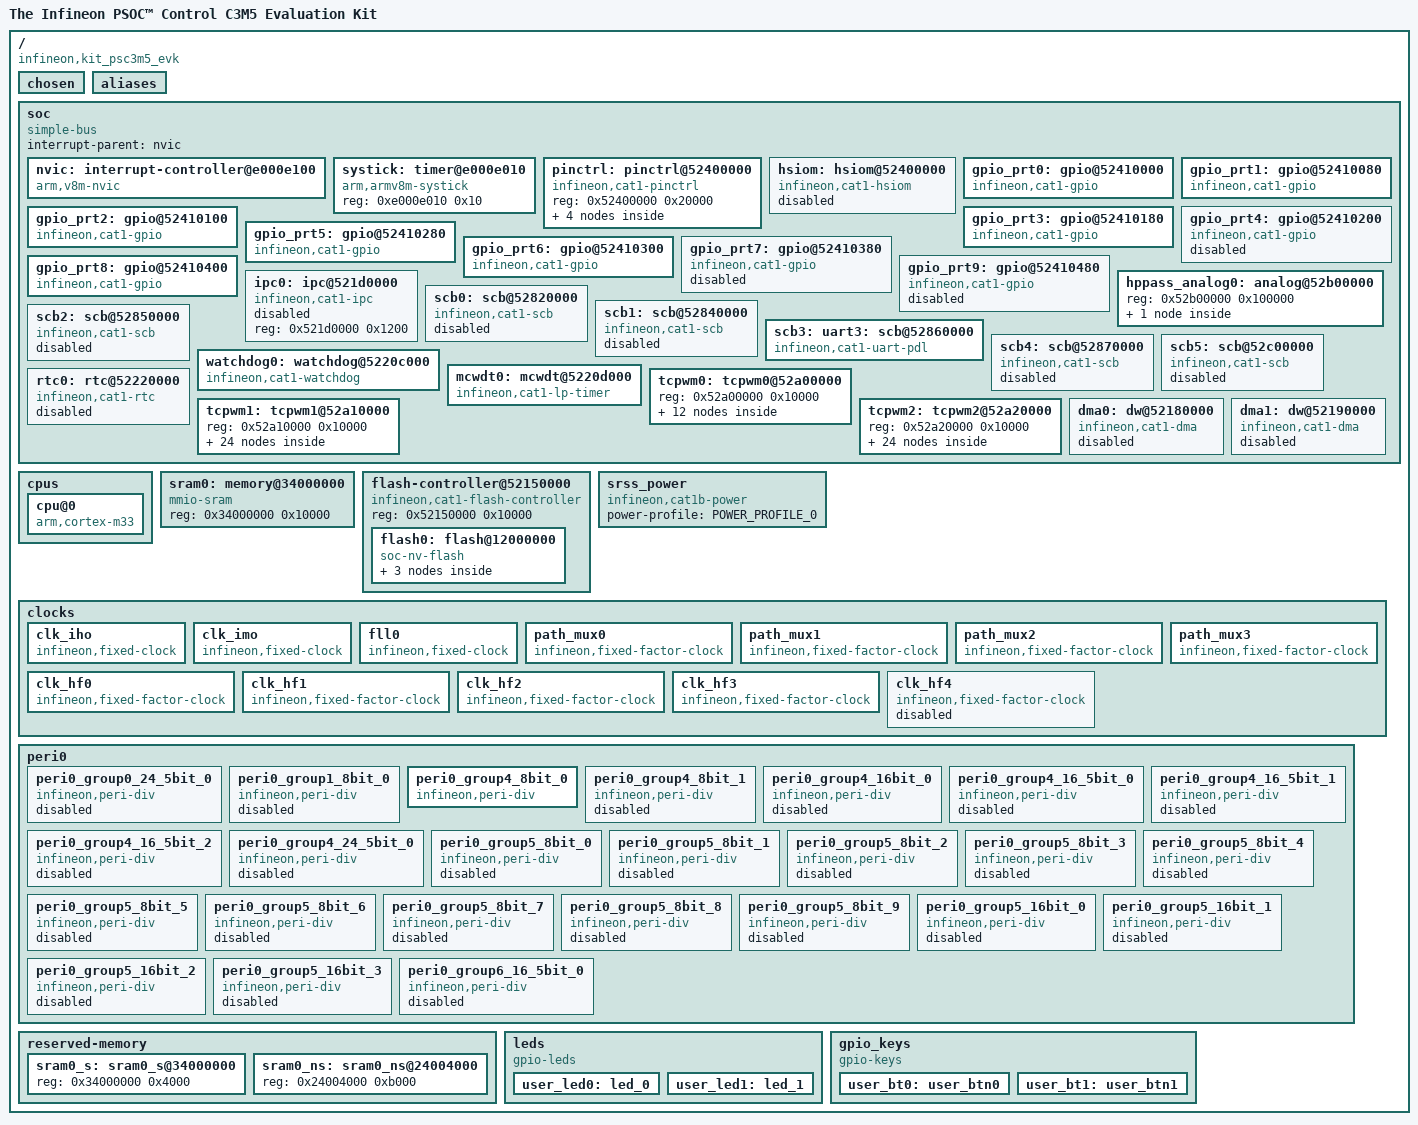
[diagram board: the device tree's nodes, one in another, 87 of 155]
/dts-v1/;

/* node '/' defined in zephyr/dts/common/skeleton.dtsi:9 */
/ {
	#address-cells = < 0x1 >;                                 /* in zephyr/dts/common/skeleton.dtsi:10 */
	#size-cells = < 0x1 >;                                    /* in zephyr/dts/common/skeleton.dtsi:11 */
	model = "The Infineon PSOC™ Control C3M5 Evaluation Kit"; /* in zephyr/boards/infineon/kit_psc3m5_evk/kit_psc3m5_evk.dts:14 */
	compatible = "infineon,kit_psc3m5_evk",
	             "infineon,PSC3M5";                           /* in zephyr/boards/infineon/kit_psc3m5_evk/kit_psc3m5_evk.dts:15 */

	/* node '/chosen' defined in zephyr/dts/common/skeleton.dtsi:13 */
	chosen {
		zephyr,sram = &sram0;            /* in zephyr/boards/infineon/kit_psc3m5_evk/kit_psc3m5_evk.dts:22 */
		zephyr,flash = &slot0_partition; /* in zephyr/boards/infineon/kit_psc3m5_evk/kit_psc3m5_evk.dts:23 */
		zephyr,console = &uart3;         /* in zephyr/boards/infineon/kit_psc3m5_evk/kit_psc3m5_evk.dts:24 */
		zephyr,shell-uart = &uart3;      /* in zephyr/boards/infineon/kit_psc3m5_evk/kit_psc3m5_evk.dts:25 */
	};

	/* node '/aliases' defined in zephyr/dts/common/skeleton.dtsi:15 */
	aliases {
		led0 = &user_led0;      /* in zephyr/boards/infineon/kit_psc3m5_evk/kit_psc3m5_evk-common.dtsi:10 */
		led1 = &user_led1;      /* in zephyr/boards/infineon/kit_psc3m5_evk/kit_psc3m5_evk-common.dtsi:11 */
		sw0 = &user_bt0;        /* in zephyr/boards/infineon/kit_psc3m5_evk/kit_psc3m5_evk-common.dtsi:12 */
		sw1 = &user_bt1;        /* in zephyr/boards/infineon/kit_psc3m5_evk/kit_psc3m5_evk-common.dtsi:13 */
		watchdog0 = &watchdog0; /* in zephyr/boards/infineon/kit_psc3m5_evk/kit_psc3m5_evk.dts:18 */
	};

	/* node '/soc' defined in zephyr/dts/arm/armv8-m.dtsi:6 */
	soc {
		#address-cells = < 0x1 >;     /* in zephyr/dts/arm/armv8-m.dtsi:7 */
		#size-cells = < 0x1 >;        /* in zephyr/dts/arm/armv8-m.dtsi:8 */
		compatible = "simple-bus";    /* in zephyr/dts/arm/armv8-m.dtsi:9 */
		interrupt-parent = < &nvic >; /* in zephyr/dts/arm/armv8-m.dtsi:10 */
		ranges;                       /* in zephyr/dts/arm/armv8-m.dtsi:11 */

		/* node '/soc/interrupt-controller@e000e100' defined in zephyr/dts/arm/armv8-m.dtsi:13 */
		nvic: interrupt-controller@e000e100 {
			#address-cells = < 0x1 >;            /* in zephyr/dts/arm/armv8-m.dtsi:14 */
			compatible = "arm,v8m-nvic";         /* in zephyr/dts/arm/armv8-m.dtsi:15 */
			reg = < 0xe000e100 0xc00 >;          /* in zephyr/dts/arm/armv8-m.dtsi:16 */
			interrupt-controller;                /* in zephyr/dts/arm/armv8-m.dtsi:17 */
			#interrupt-cells = < 0x2 >;          /* in zephyr/dts/arm/armv8-m.dtsi:18 */
			arm,num-irq-priority-bits = < 0x3 >; /* in zephyr/dts/arm/infineon/cat1b/psc3/psc3.cm33.dtsi:26 */
			phandle = < 0x1 >;                   /* in zephyr/dts/arm/armv8-m.dtsi:10 */
		};

		/* node '/soc/timer@e000e010' defined in zephyr/dts/arm/armv8-m.dtsi:21 */
		systick: timer@e000e010 {
			compatible = "arm,armv8m-systick"; /* in zephyr/dts/arm/armv8-m.dtsi:22 */
			reg = < 0xe000e010 0x10 >;         /* in zephyr/dts/arm/armv8-m.dtsi:23 */
		};

		/* node '/soc/pinctrl@52400000' defined in zephyr/dts/arm/infineon/cat1b/psc3/psc3_s.dtsi:19 */
		pinctrl: pinctrl@52400000 {
			compatible = "infineon,cat1-pinctrl"; /* in zephyr/dts/arm/infineon/cat1b/psc3/psc3_s.dtsi:20 */
			reg = < 0x52400000 0x20000 >;         /* in zephyr/dts/arm/infineon/cat1b/psc3/psc3_s.dtsi:21 */

			/* node '/soc/pinctrl@52400000/p6_0_scb3_uart_cts' defined in zephyr/dts/arm/infineon/cat1b/psc3/psc3.e-lqfp-80_s.dtsi:459 */
			p6_0_scb3_uart_cts: p6_0_scb3_uart_cts {
				pinmux = < 0x100006 >; /* in zephyr/dts/arm/infineon/cat1b/psc3/psc3.e-lqfp-80_s.dtsi:460 */
				input-enable;          /* in zephyr/boards/infineon/kit_psc3m5_evk/kit_psc3m5_evk-pinctrl.dtsi:20 */
				phandle = < 0x6 >;     /* in zephyr/boards/infineon/kit_psc3m5_evk/kit_psc3m5_evk.dts:36 */
			};

			/* node '/soc/pinctrl@52400000/p6_1_scb3_uart_rts' defined in zephyr/dts/arm/infineon/cat1b/psc3/psc3.e-lqfp-80_s.dtsi:496 */
			p6_1_scb3_uart_rts: p6_1_scb3_uart_rts {
				pinmux = < 0x100106 >; /* in zephyr/dts/arm/infineon/cat1b/psc3/psc3.e-lqfp-80_s.dtsi:497 */
				drive-push-pull;       /* in zephyr/boards/infineon/kit_psc3m5_evk/kit_psc3m5_evk-pinctrl.dtsi:16 */
				phandle = < 0x5 >;     /* in zephyr/boards/infineon/kit_psc3m5_evk/kit_psc3m5_evk.dts:36 */
			};

			/* node '/soc/pinctrl@52400000/p6_2_scb3_uart_rx' defined in zephyr/dts/arm/infineon/cat1b/psc3/psc3.e-lqfp-80_s.dtsi:533 */
			p6_2_scb3_uart_rx: p6_2_scb3_uart_rx {
				pinmux = < 0x100206 >; /* in zephyr/dts/arm/infineon/cat1b/psc3/psc3.e-lqfp-80_s.dtsi:534 */
				input-enable;          /* in zephyr/boards/infineon/kit_psc3m5_evk/kit_psc3m5_evk-pinctrl.dtsi:12 */
				phandle = < 0x4 >;     /* in zephyr/boards/infineon/kit_psc3m5_evk/kit_psc3m5_evk.dts:36 */
			};

			/* node '/soc/pinctrl@52400000/p6_3_scb3_uart_tx' defined in zephyr/dts/arm/infineon/cat1b/psc3/psc3.e-lqfp-80_s.dtsi:570 */
			p6_3_scb3_uart_tx: p6_3_scb3_uart_tx {
				pinmux = < 0x100306 >; /* in zephyr/dts/arm/infineon/cat1b/psc3/psc3.e-lqfp-80_s.dtsi:571 */
				drive-push-pull;       /* in zephyr/boards/infineon/kit_psc3m5_evk/kit_psc3m5_evk-pinctrl.dtsi:8 */
				phandle = < 0x3 >;     /* in zephyr/boards/infineon/kit_psc3m5_evk/kit_psc3m5_evk.dts:36 */
			};
		};

		/* node '/soc/hsiom@52400000' defined in zephyr/dts/arm/infineon/cat1b/psc3/psc3_s.dtsi:24 */
		hsiom: hsiom@52400000 {
			compatible = "infineon,cat1-hsiom"; /* in zephyr/dts/arm/infineon/cat1b/psc3/psc3_s.dtsi:25 */
			reg = < 0x52400000 0x4000 >;        /* in zephyr/dts/arm/infineon/cat1b/psc3/psc3_s.dtsi:26 */
			interrupts = < 0x16 0x4 >,
			             < 0x14 0x4 >;          /* in zephyr/dts/arm/infineon/cat1b/psc3/psc3_s.dtsi:27 */
			status = "disabled";                /* in zephyr/dts/arm/infineon/cat1b/psc3/psc3_s.dtsi:28 */
		};

		/* node '/soc/gpio@52410000' defined in zephyr/dts/arm/infineon/cat1b/psc3/psc3_s.dtsi:31 */
		gpio_prt0: gpio@52410000 {
			compatible = "infineon,cat1-gpio"; /* in zephyr/dts/arm/infineon/cat1b/psc3/psc3_s.dtsi:32 */
			reg = < 0x52410000 0x80 >;         /* in zephyr/dts/arm/infineon/cat1b/psc3/psc3_s.dtsi:33 */
			interrupts = < 0xa 0x4 >;          /* in zephyr/dts/arm/infineon/cat1b/psc3/psc3_s.dtsi:34 */
			gpio-controller;                   /* in zephyr/dts/arm/infineon/cat1b/psc3/psc3_s.dtsi:35 */
			ngpios = < 0x2 >;                  /* in zephyr/dts/arm/infineon/cat1b/psc3/psc3_s.dtsi:36 */
			#gpio-cells = < 0x2 >;             /* in zephyr/dts/arm/infineon/cat1b/psc3/psc3_s.dtsi:38 */
			status = "okay";                   /* in zephyr/boards/infineon/kit_psc3m5_evk/kit_psc3m5_evk-common.dtsi:48 */
		};

		/* node '/soc/gpio@52410080' defined in zephyr/dts/arm/infineon/cat1b/psc3/psc3_s.dtsi:41 */
		gpio_prt1: gpio@52410080 {
			compatible = "infineon,cat1-gpio"; /* in zephyr/dts/arm/infineon/cat1b/psc3/psc3_s.dtsi:42 */
			reg = < 0x52410080 0x80 >;         /* in zephyr/dts/arm/infineon/cat1b/psc3/psc3_s.dtsi:43 */
			interrupts = < 0xb 0x4 >;          /* in zephyr/dts/arm/infineon/cat1b/psc3/psc3_s.dtsi:44 */
			gpio-controller;                   /* in zephyr/dts/arm/infineon/cat1b/psc3/psc3_s.dtsi:45 */
			ngpios = < 0x4 >;                  /* in zephyr/dts/arm/infineon/cat1b/psc3/psc3_s.dtsi:46 */
			#gpio-cells = < 0x2 >;             /* in zephyr/dts/arm/infineon/cat1b/psc3/psc3_s.dtsi:48 */
			status = "okay";                   /* in zephyr/boards/infineon/kit_psc3m5_evk/kit_psc3m5_evk-common.dtsi:52 */
		};

		/* node '/soc/gpio@52410100' defined in zephyr/dts/arm/infineon/cat1b/psc3/psc3_s.dtsi:51 */
		gpio_prt2: gpio@52410100 {
			compatible = "infineon,cat1-gpio"; /* in zephyr/dts/arm/infineon/cat1b/psc3/psc3_s.dtsi:52 */
			reg = < 0x52410100 0x80 >;         /* in zephyr/dts/arm/infineon/cat1b/psc3/psc3_s.dtsi:53 */
			interrupts = < 0xc 0x4 >;          /* in zephyr/dts/arm/infineon/cat1b/psc3/psc3_s.dtsi:54 */
			gpio-controller;                   /* in zephyr/dts/arm/infineon/cat1b/psc3/psc3_s.dtsi:55 */
			ngpios = < 0x4 >;                  /* in zephyr/dts/arm/infineon/cat1b/psc3/psc3_s.dtsi:56 */
			#gpio-cells = < 0x2 >;             /* in zephyr/dts/arm/infineon/cat1b/psc3/psc3_s.dtsi:58 */
			status = "okay";                   /* in zephyr/boards/infineon/kit_psc3m5_evk/kit_psc3m5_evk-common.dtsi:56 */
			phandle = < 0xd >;                 /* in zephyr/boards/infineon/kit_psc3m5_evk/kit_psc3m5_evk-common.dtsi:41 */
		};

		/* node '/soc/gpio@52410180' defined in zephyr/dts/arm/infineon/cat1b/psc3/psc3_s.dtsi:61 */
		gpio_prt3: gpio@52410180 {
			compatible = "infineon,cat1-gpio"; /* in zephyr/dts/arm/infineon/cat1b/psc3/psc3_s.dtsi:62 */
			reg = < 0x52410180 0x80 >;         /* in zephyr/dts/arm/infineon/cat1b/psc3/psc3_s.dtsi:63 */
			interrupts = < 0xd 0x4 >;          /* in zephyr/dts/arm/infineon/cat1b/psc3/psc3_s.dtsi:64 */
			gpio-controller;                   /* in zephyr/dts/arm/infineon/cat1b/psc3/psc3_s.dtsi:65 */
			ngpios = < 0x4 >;                  /* in zephyr/dts/arm/infineon/cat1b/psc3/psc3_s.dtsi:66 */
			#gpio-cells = < 0x2 >;             /* in zephyr/dts/arm/infineon/cat1b/psc3/psc3_s.dtsi:68 */
			status = "okay";                   /* in zephyr/boards/infineon/kit_psc3m5_evk/kit_psc3m5_evk-common.dtsi:60 */
		};

		/* node '/soc/gpio@52410200' defined in zephyr/dts/arm/infineon/cat1b/psc3/psc3_s.dtsi:71 */
		gpio_prt4: gpio@52410200 {
			compatible = "infineon,cat1-gpio"; /* in zephyr/dts/arm/infineon/cat1b/psc3/psc3_s.dtsi:72 */
			reg = < 0x52410200 0x80 >;         /* in zephyr/dts/arm/infineon/cat1b/psc3/psc3_s.dtsi:73 */
			interrupts = < 0xe 0x4 >;          /* in zephyr/dts/arm/infineon/cat1b/psc3/psc3_s.dtsi:74 */
			gpio-controller;                   /* in zephyr/dts/arm/infineon/cat1b/psc3/psc3_s.dtsi:75 */
			ngpios = < 0x8 >;                  /* in zephyr/dts/arm/infineon/cat1b/psc3/psc3_s.dtsi:76 */
			status = "disabled";               /* in zephyr/dts/arm/infineon/cat1b/psc3/psc3_s.dtsi:77 */
			#gpio-cells = < 0x2 >;             /* in zephyr/dts/arm/infineon/cat1b/psc3/psc3_s.dtsi:78 */
		};

		/* node '/soc/gpio@52410280' defined in zephyr/dts/arm/infineon/cat1b/psc3/psc3_s.dtsi:81 */
		gpio_prt5: gpio@52410280 {
			compatible = "infineon,cat1-gpio"; /* in zephyr/dts/arm/infineon/cat1b/psc3/psc3_s.dtsi:82 */
			reg = < 0x52410280 0x80 >;         /* in zephyr/dts/arm/infineon/cat1b/psc3/psc3_s.dtsi:83 */
			interrupts = < 0xf 0x4 >;          /* in zephyr/dts/arm/infineon/cat1b/psc3/psc3_s.dtsi:84 */
			gpio-controller;                   /* in zephyr/dts/arm/infineon/cat1b/psc3/psc3_s.dtsi:85 */
			ngpios = < 0x4 >;                  /* in zephyr/dts/arm/infineon/cat1b/psc3/psc3_s.dtsi:86 */
			#gpio-cells = < 0x2 >;             /* in zephyr/dts/arm/infineon/cat1b/psc3/psc3_s.dtsi:88 */
			status = "okay";                   /* in zephyr/boards/infineon/kit_psc3m5_evk/kit_psc3m5_evk-common.dtsi:64 */
			phandle = < 0xc >;                 /* in zephyr/boards/infineon/kit_psc3m5_evk/kit_psc3m5_evk-common.dtsi:35 */
		};

		/* node '/soc/gpio@52410300' defined in zephyr/dts/arm/infineon/cat1b/psc3/psc3_s.dtsi:91 */
		gpio_prt6: gpio@52410300 {
			compatible = "infineon,cat1-gpio"; /* in zephyr/dts/arm/infineon/cat1b/psc3/psc3_s.dtsi:92 */
			reg = < 0x52410300 0x80 >;         /* in zephyr/dts/arm/infineon/cat1b/psc3/psc3_s.dtsi:93 */
			interrupts = < 0x10 0x4 >;         /* in zephyr/dts/arm/infineon/cat1b/psc3/psc3_s.dtsi:94 */
			gpio-controller;                   /* in zephyr/dts/arm/infineon/cat1b/psc3/psc3_s.dtsi:95 */
			ngpios = < 0x4 >;                  /* in zephyr/dts/arm/infineon/cat1b/psc3/psc3_s.dtsi:96 */
			#gpio-cells = < 0x2 >;             /* in zephyr/dts/arm/infineon/cat1b/psc3/psc3_s.dtsi:98 */
			status = "okay";                   /* in zephyr/boards/infineon/kit_psc3m5_evk/kit_psc3m5_evk-common.dtsi:68 */
		};

		/* node '/soc/gpio@52410380' defined in zephyr/dts/arm/infineon/cat1b/psc3/psc3_s.dtsi:101 */
		gpio_prt7: gpio@52410380 {
			compatible = "infineon,cat1-gpio"; /* in zephyr/dts/arm/infineon/cat1b/psc3/psc3_s.dtsi:102 */
			reg = < 0x52410380 0x80 >;         /* in zephyr/dts/arm/infineon/cat1b/psc3/psc3_s.dtsi:103 */
			interrupts = < 0x11 0x4 >;         /* in zephyr/dts/arm/infineon/cat1b/psc3/psc3_s.dtsi:104 */
			gpio-controller;                   /* in zephyr/dts/arm/infineon/cat1b/psc3/psc3_s.dtsi:105 */
			ngpios = < 0x8 >;                  /* in zephyr/dts/arm/infineon/cat1b/psc3/psc3_s.dtsi:106 */
			status = "disabled";               /* in zephyr/dts/arm/infineon/cat1b/psc3/psc3_s.dtsi:107 */
			#gpio-cells = < 0x2 >;             /* in zephyr/dts/arm/infineon/cat1b/psc3/psc3_s.dtsi:108 */
		};

		/* node '/soc/gpio@52410400' defined in zephyr/dts/arm/infineon/cat1b/psc3/psc3_s.dtsi:111 */
		gpio_prt8: gpio@52410400 {
			compatible = "infineon,cat1-gpio"; /* in zephyr/dts/arm/infineon/cat1b/psc3/psc3_s.dtsi:112 */
			reg = < 0x52410400 0x80 >;         /* in zephyr/dts/arm/infineon/cat1b/psc3/psc3_s.dtsi:113 */
			interrupts = < 0x12 0x4 >;         /* in zephyr/dts/arm/infineon/cat1b/psc3/psc3_s.dtsi:114 */
			gpio-controller;                   /* in zephyr/dts/arm/infineon/cat1b/psc3/psc3_s.dtsi:115 */
			ngpios = < 0x6 >;                  /* in zephyr/dts/arm/infineon/cat1b/psc3/psc3_s.dtsi:116 */
			#gpio-cells = < 0x2 >;             /* in zephyr/dts/arm/infineon/cat1b/psc3/psc3_s.dtsi:118 */
			status = "okay";                   /* in zephyr/boards/infineon/kit_psc3m5_evk/kit_psc3m5_evk-common.dtsi:72 */
			phandle = < 0xb >;                 /* in zephyr/boards/infineon/kit_psc3m5_evk/kit_psc3m5_evk-common.dtsi:21 */
		};

		/* node '/soc/gpio@52410480' defined in zephyr/dts/arm/infineon/cat1b/psc3/psc3_s.dtsi:121 */
		gpio_prt9: gpio@52410480 {
			compatible = "infineon,cat1-gpio"; /* in zephyr/dts/arm/infineon/cat1b/psc3/psc3_s.dtsi:122 */
			reg = < 0x52410480 0x80 >;         /* in zephyr/dts/arm/infineon/cat1b/psc3/psc3_s.dtsi:123 */
			interrupts = < 0x13 0x4 >;         /* in zephyr/dts/arm/infineon/cat1b/psc3/psc3_s.dtsi:124 */
			gpio-controller;                   /* in zephyr/dts/arm/infineon/cat1b/psc3/psc3_s.dtsi:125 */
			ngpios = < 0x6 >;                  /* in zephyr/dts/arm/infineon/cat1b/psc3/psc3_s.dtsi:126 */
			status = "disabled";               /* in zephyr/dts/arm/infineon/cat1b/psc3/psc3_s.dtsi:127 */
			#gpio-cells = < 0x2 >;             /* in zephyr/dts/arm/infineon/cat1b/psc3/psc3_s.dtsi:128 */
		};

		/* node '/soc/analog@52b00000' defined in zephyr/dts/arm/infineon/cat1b/psc3/psc3_s.dtsi:131 */
		hppass_analog0: analog@52b00000 {
			reg = < 0x52b00000 0x100000 >; /* in zephyr/dts/arm/infineon/cat1b/psc3/psc3_s.dtsi:132 */
			#address-cells = < 0x1 >;      /* in zephyr/dts/arm/infineon/cat1b/psc3/psc3_s.dtsi:133 */
			#size-cells = < 0x1 >;         /* in zephyr/dts/arm/infineon/cat1b/psc3/psc3_s.dtsi:134 */
			ranges;                        /* in zephyr/dts/arm/infineon/cat1b/psc3/psc3_s.dtsi:135 */

			/* node '/soc/analog@52b00000/adc@70000' defined in zephyr/dts/arm/infineon/cat1b/psc3/psc3_s.dtsi:137 */
			adc0: adc@70000 {
				compatible = "infineon,hppass-sar-adc"; /* in zephyr/dts/arm/infineon/cat1b/psc3/psc3_s.dtsi:138 */
				reg = < 0x70000 0x10000 >;              /* in zephyr/dts/arm/infineon/cat1b/psc3/psc3_s.dtsi:140 */
				interrupts = < 0x6d 0x4 >;              /* in zephyr/dts/arm/infineon/cat1b/psc3/psc3_s.dtsi:141 */
				status = "disabled";                    /* in zephyr/dts/arm/infineon/cat1b/psc3/psc3_s.dtsi:142 */
				#io-channel-cells = < 0x1 >;            /* in zephyr/dts/arm/infineon/cat1b/psc3/psc3_s.dtsi:143 */
			};
		};

		/* node '/soc/ipc@521d0000' defined in zephyr/dts/arm/infineon/cat1b/psc3/psc3_s.dtsi:147 */
		ipc0: ipc@521d0000 {
			compatible = "infineon,cat1-ipc"; /* in zephyr/dts/arm/infineon/cat1b/psc3/psc3_s.dtsi:148 */
			reg = < 0x521d0000 0x1200 >;      /* in zephyr/dts/arm/infineon/cat1b/psc3/psc3_s.dtsi:149 */
			status = "disabled";              /* in zephyr/dts/arm/infineon/cat1b/psc3/psc3_s.dtsi:150 */
			#ipc-config-cells = < 0x3 >;      /* in zephyr/dts/arm/infineon/cat1b/psc3/psc3_s.dtsi:151 */
		};

		/* node '/soc/scb@52820000' defined in zephyr/dts/arm/infineon/cat1b/psc3/psc3_s.dtsi:154 */
		scb0: scb@52820000 {
			compatible = "infineon,cat1-scb"; /* in zephyr/dts/arm/infineon/cat1b/psc3/psc3_s.dtsi:155 */
			reg = < 0x52820000 0xfd0 >;       /* in zephyr/dts/arm/infineon/cat1b/psc3/psc3_s.dtsi:156 */
			interrupts = < 0x17 0x4 >;        /* in zephyr/dts/arm/infineon/cat1b/psc3/psc3_s.dtsi:157 */
			status = "disabled";              /* in zephyr/dts/arm/infineon/cat1b/psc3/psc3_s.dtsi:158 */
		};

		/* node '/soc/scb@52840000' defined in zephyr/dts/arm/infineon/cat1b/psc3/psc3_s.dtsi:161 */
		scb1: scb@52840000 {
			compatible = "infineon,cat1-scb"; /* in zephyr/dts/arm/infineon/cat1b/psc3/psc3_s.dtsi:162 */
			reg = < 0x52840000 0xfd0 >;       /* in zephyr/dts/arm/infineon/cat1b/psc3/psc3_s.dtsi:163 */
			interrupts = < 0x1f 0x4 >;        /* in zephyr/dts/arm/infineon/cat1b/psc3/psc3_s.dtsi:164 */
			status = "disabled";              /* in zephyr/dts/arm/infineon/cat1b/psc3/psc3_s.dtsi:165 */
		};

		/* node '/soc/scb@52850000' defined in zephyr/dts/arm/infineon/cat1b/psc3/psc3_s.dtsi:168 */
		scb2: scb@52850000 {
			compatible = "infineon,cat1-scb"; /* in zephyr/dts/arm/infineon/cat1b/psc3/psc3_s.dtsi:169 */
			reg = < 0x52850000 0xfd0 >;       /* in zephyr/dts/arm/infineon/cat1b/psc3/psc3_s.dtsi:170 */
			interrupts = < 0x20 0x4 >;        /* in zephyr/dts/arm/infineon/cat1b/psc3/psc3_s.dtsi:171 */
			status = "disabled";              /* in zephyr/dts/arm/infineon/cat1b/psc3/psc3_s.dtsi:172 */
		};

		/* node '/soc/scb@52860000' defined in zephyr/dts/arm/infineon/cat1b/psc3/psc3_s.dtsi:175 */
		scb3: uart3: scb@52860000 {
			reg = < 0x52860000 0xfd0 >;                                                                    /* in zephyr/dts/arm/infineon/cat1b/psc3/psc3_s.dtsi:177 */
			interrupts = < 0x21 0x4 >;                                                                     /* in zephyr/dts/arm/infineon/cat1b/psc3/psc3_s.dtsi:178 */
			compatible = "infineon,cat1-uart-pdl";                                                         /* in zephyr/boards/infineon/kit_psc3m5_evk/kit_psc3m5_evk.dts:30 */
			status = "okay";                                                                               /* in zephyr/boards/infineon/kit_psc3m5_evk/kit_psc3m5_evk.dts:31 */
			current-speed = < 0x1c200 >;                                                                   /* in zephyr/boards/infineon/kit_psc3m5_evk/kit_psc3m5_evk.dts:32 */
			clocks = < &peri0_group4_8bit_0 >;                                                             /* in zephyr/boards/infineon/kit_psc3m5_evk/kit_psc3m5_evk.dts:34 */
			pinctrl-0 = < &p6_3_scb3_uart_tx &p6_2_scb3_uart_rx &p6_1_scb3_uart_rts &p6_0_scb3_uart_cts >; /* in zephyr/boards/infineon/kit_psc3m5_evk/kit_psc3m5_evk.dts:36 */
			pinctrl-names = "default";                                                                     /* in zephyr/boards/infineon/kit_psc3m5_evk/kit_psc3m5_evk.dts:37 */
		};

		/* node '/soc/scb@52870000' defined in zephyr/dts/arm/infineon/cat1b/psc3/psc3_s.dtsi:182 */
		scb4: scb@52870000 {
			compatible = "infineon,cat1-scb"; /* in zephyr/dts/arm/infineon/cat1b/psc3/psc3_s.dtsi:183 */
			reg = < 0x52870000 0xfd0 >;       /* in zephyr/dts/arm/infineon/cat1b/psc3/psc3_s.dtsi:184 */
			interrupts = < 0x22 0x4 >;        /* in zephyr/dts/arm/infineon/cat1b/psc3/psc3_s.dtsi:185 */
			status = "disabled";              /* in zephyr/dts/arm/infineon/cat1b/psc3/psc3_s.dtsi:186 */
		};

		/* node '/soc/scb@52c00000' defined in zephyr/dts/arm/infineon/cat1b/psc3/psc3_s.dtsi:189 */
		scb5: scb@52c00000 {
			compatible = "infineon,cat1-scb"; /* in zephyr/dts/arm/infineon/cat1b/psc3/psc3_s.dtsi:190 */
			reg = < 0x52c00000 0xfd0 >;       /* in zephyr/dts/arm/infineon/cat1b/psc3/psc3_s.dtsi:191 */
			interrupts = < 0x23 0x4 >;        /* in zephyr/dts/arm/infineon/cat1b/psc3/psc3_s.dtsi:192 */
			status = "disabled";              /* in zephyr/dts/arm/infineon/cat1b/psc3/psc3_s.dtsi:193 */
		};

		/* node '/soc/watchdog@5220c000' defined in zephyr/dts/arm/infineon/cat1b/psc3/psc3_s.dtsi:196 */
		watchdog0: watchdog@5220c000 {
			compatible = "infineon,cat1-watchdog"; /* in zephyr/dts/arm/infineon/cat1b/psc3/psc3_s.dtsi:197 */
			reg = < 0x5220c000 0x10 >;             /* in zephyr/dts/arm/infineon/cat1b/psc3/psc3_s.dtsi:198 */
			interrupts = < 0x1c 0x4 >;             /* in zephyr/dts/arm/infineon/cat1b/psc3/psc3_s.dtsi:199 */
			status = "okay";                       /* in zephyr/boards/infineon/kit_psc3m5_evk/kit_psc3m5_evk.dts:80 */
		};

		/* node '/soc/mcwdt@5220d000' defined in zephyr/dts/arm/infineon/cat1b/psc3/psc3_s.dtsi:203 */
		mcwdt0: mcwdt@5220d000 {
			compatible = "infineon,cat1-lp-timer"; /* in zephyr/dts/arm/infineon/cat1b/psc3/psc3_s.dtsi:204 */
			reg = < 0x5220d000 0x40 >;             /* in zephyr/dts/arm/infineon/cat1b/psc3/psc3_s.dtsi:205 */
			interrupts = < 0x18 0x4 >;             /* in zephyr/dts/arm/infineon/cat1b/psc3/psc3_s.dtsi:206 */
			status = "okay";                       /* in zephyr/boards/infineon/kit_psc3m5_evk/kit_psc3m5_evk.dts:84 */
		};

		/* node '/soc/rtc@52220000' defined in zephyr/dts/arm/infineon/cat1b/psc3/psc3_s.dtsi:210 */
		rtc0: rtc@52220000 {
			compatible = "infineon,cat1-rtc"; /* in zephyr/dts/arm/infineon/cat1b/psc3/psc3_s.dtsi:211 */
			reg = < 0x52220000 0xff0c >;      /* in zephyr/dts/arm/infineon/cat1b/psc3/psc3_s.dtsi:212 */
			interrupts = < 0x19 0x4 >;        /* in zephyr/dts/arm/infineon/cat1b/psc3/psc3_s.dtsi:213 */
			alarms-count = < 0x2 >;           /* in zephyr/dts/arm/infineon/cat1b/psc3/psc3_s.dtsi:214 */
			status = "disabled";              /* in zephyr/dts/arm/infineon/cat1b/psc3/psc3_s.dtsi:215 */
		};

		/* node '/soc/tcpwm0@52a00000' defined in zephyr/dts/arm/infineon/cat1b/psc3/psc3_s.dtsi:218 */
		tcpwm0: tcpwm0@52a00000 {
			reg = < 0x52a00000 0x10000 >; /* in zephyr/dts/arm/infineon/cat1b/psc3/psc3_s.dtsi:219 */
			#address-cells = < 0x1 >;     /* in zephyr/dts/arm/infineon/cat1b/psc3/psc3_s.dtsi:220 */
			#size-cells = < 0x1 >;        /* in zephyr/dts/arm/infineon/cat1b/psc3/psc3_s.dtsi:221 */

			/* node '/soc/tcpwm0@52a00000/tcpwm0_0@52a00000' defined in zephyr/dts/arm/infineon/cat1b/psc3/psc3_s.dtsi:223 */
			tcpwm0_0: tcpwm0_0@52a00000 {
				compatible = "infineon,tcpwm"; /* in zephyr/dts/arm/infineon/cat1b/psc3/psc3_s.dtsi:224 */
				reg = < 0x52a00000 0x100 >;    /* in zephyr/dts/arm/infineon/cat1b/psc3/psc3_s.dtsi:225 */
				interrupts = < 0x4c 0x4 >;     /* in zephyr/dts/arm/infineon/cat1b/psc3/psc3_s.dtsi:226 */
				resolution = < 0x20 >;         /* in zephyr/dts/arm/infineon/cat1b/psc3/psc3_s.dtsi:227 */
				status = "disabled";           /* in zephyr/dts/arm/infineon/cat1b/psc3/psc3_s.dtsi:228 */

				/* node '/soc/tcpwm0@52a00000/tcpwm0_0@52a00000/pwm0_0' defined in zephyr/dts/arm/infineon/cat1b/psc3/psc3_s.dtsi:230 */
				pwm0_0: pwm0_0 {
					compatible = "infineon,tcpwm-pwm"; /* in zephyr/dts/arm/infineon/cat1b/psc3/psc3_s.dtsi:231 */
					#pwm-cells = < 0x3 >;              /* in zephyr/dts/arm/infineon/cat1b/psc3/psc3_s.dtsi:232 */
					status = "disabled";               /* in zephyr/dts/arm/infineon/cat1b/psc3/psc3_s.dtsi:233 */
				};

				/* node '/soc/tcpwm0@52a00000/tcpwm0_0@52a00000/counter0_0' defined in zephyr/dts/arm/infineon/cat1b/psc3/psc3_s.dtsi:236 */
				counter0_0: counter0_0 {
					compatible = "infineon,tcpwm-counter"; /* in zephyr/dts/arm/infineon/cat1b/psc3/psc3_s.dtsi:237 */
					status = "disabled";                   /* in zephyr/dts/arm/infineon/cat1b/psc3/psc3_s.dtsi:238 */
				};
			};

			/* node '/soc/tcpwm0@52a00000/tcpwm0_1@52a00100' defined in zephyr/dts/arm/infineon/cat1b/psc3/psc3_s.dtsi:242 */
			tcpwm0_1: tcpwm0_1@52a00100 {
				compatible = "infineon,tcpwm"; /* in zephyr/dts/arm/infineon/cat1b/psc3/psc3_s.dtsi:243 */
				reg = < 0x52a00100 0x100 >;    /* in zephyr/dts/arm/infineon/cat1b/psc3/psc3_s.dtsi:244 */
				interrupts = < 0x4d 0x4 >;     /* in zephyr/dts/arm/infineon/cat1b/psc3/psc3_s.dtsi:245 */
				resolution = < 0x20 >;         /* in zephyr/dts/arm/infineon/cat1b/psc3/psc3_s.dtsi:246 */
				status = "disabled";           /* in zephyr/dts/arm/infineon/cat1b/psc3/psc3_s.dtsi:247 */

				/* node '/soc/tcpwm0@52a00000/tcpwm0_1@52a00100/pwm0_1' defined in zephyr/dts/arm/infineon/cat1b/psc3/psc3_s.dtsi:249 */
				pwm0_1: pwm0_1 {
					compatible = "infineon,tcpwm-pwm"; /* in zephyr/dts/arm/infineon/cat1b/psc3/psc3_s.dtsi:250 */
					#pwm-cells = < 0x3 >;              /* in zephyr/dts/arm/infineon/cat1b/psc3/psc3_s.dtsi:251 */
					status = "disabled";               /* in zephyr/dts/arm/infineon/cat1b/psc3/psc3_s.dtsi:252 */
				};

				/* node '/soc/tcpwm0@52a00000/tcpwm0_1@52a00100/counter0_1' defined in zephyr/dts/arm/infineon/cat1b/psc3/psc3_s.dtsi:255 */
				counter0_1: counter0_1 {
					compatible = "infineon,tcpwm-counter"; /* in zephyr/dts/arm/infineon/cat1b/psc3/psc3_s.dtsi:256 */
					status = "disabled";                   /* in zephyr/dts/arm/infineon/cat1b/psc3/psc3_s.dtsi:257 */
				};
			};

			/* node '/soc/tcpwm0@52a00000/tcpwm0_2@52a00200' defined in zephyr/dts/arm/infineon/cat1b/psc3/psc3_s.dtsi:261 */
			tcpwm0_2: tcpwm0_2@52a00200 {
				compatible = "infineon,tcpwm"; /* in zephyr/dts/arm/infineon/cat1b/psc3/psc3_s.dtsi:262 */
				reg = < 0x52a00200 0x100 >;    /* in zephyr/dts/arm/infineon/cat1b/psc3/psc3_s.dtsi:263 */
				interrupts = < 0x4e 0x4 >;     /* in zephyr/dts/arm/infineon/cat1b/psc3/psc3_s.dtsi:264 */
				resolution = < 0x20 >;         /* in zephyr/dts/arm/infineon/cat1b/psc3/psc3_s.dtsi:265 */
				status = "disabled";           /* in zephyr/dts/arm/infineon/cat1b/psc3/psc3_s.dtsi:266 */

				/* node '/soc/tcpwm0@52a00000/tcpwm0_2@52a00200/pwm0_2' defined in zephyr/dts/arm/infineon/cat1b/psc3/psc3_s.dtsi:268 */
				pwm0_2: pwm0_2 {
					compatible = "infineon,tcpwm-pwm"; /* in zephyr/dts/arm/infineon/cat1b/psc3/psc3_s.dtsi:269 */
					#pwm-cells = < 0x3 >;              /* in zephyr/dts/arm/infineon/cat1b/psc3/psc3_s.dtsi:270 */
					status = "disabled";               /* in zephyr/dts/arm/infineon/cat1b/psc3/psc3_s.dtsi:271 */
				};

				/* node '/soc/tcpwm0@52a00000/tcpwm0_2@52a00200/counter0_2' defined in zephyr/dts/arm/infineon/cat1b/psc3/psc3_s.dtsi:274 */
				counter0_2: counter0_2 {
					compatible = "infineon,tcpwm-counter"; /* in zephyr/dts/arm/infineon/cat1b/psc3/psc3_s.dtsi:275 */
					status = "disabled";                   /* in zephyr/dts/arm/infineon/cat1b/psc3/psc3_s.dtsi:276 */
				};
			};

			/* node '/soc/tcpwm0@52a00000/tcpwm0_3@52a00300' defined in zephyr/dts/arm/infineon/cat1b/psc3/psc3_s.dtsi:280 */
			tcpwm0_3: tcpwm0_3@52a00300 {
				compatible = "infineon,tcpwm"; /* in zephyr/dts/arm/infineon/cat1b/psc3/psc3_s.dtsi:281 */
				reg = < 0x52a00300 0x100 >;    /* in zephyr/dts/arm/infineon/cat1b/psc3/psc3_s.dtsi:282 */
				interrupts = < 0x4f 0x4 >;     /* in zephyr/dts/arm/infineon/cat1b/psc3/psc3_s.dtsi:283 */
				resolution = < 0x20 >;         /* in zephyr/dts/arm/infineon/cat1b/psc3/psc3_s.dtsi:284 */
				status = "disabled";           /* in zephyr/dts/arm/infineon/cat1b/psc3/psc3_s.dtsi:285 */

				/* node '/soc/tcpwm0@52a00000/tcpwm0_3@52a00300/pwm0_3' defined in zephyr/dts/arm/infineon/cat1b/psc3/psc3_s.dtsi:287 */
				pwm0_3: pwm0_3 {
					compatible = "infineon,tcpwm-pwm"; /* in zephyr/dts/arm/infineon/cat1b/psc3/psc3_s.dtsi:288 */
					#pwm-cells = < 0x3 >;              /* in zephyr/dts/arm/infineon/cat1b/psc3/psc3_s.dtsi:289 */
					status = "disabled";               /* in zephyr/dts/arm/infineon/cat1b/psc3/psc3_s.dtsi:290 */
				};

				/* node '/soc/tcpwm0@52a00000/tcpwm0_3@52a00300/counter0_3' defined in zephyr/dts/arm/infineon/cat1b/psc3/psc3_s.dtsi:293 */
				counter0_3: counter0_3 {
					compatible = "infineon,tcpwm-counter"; /* in zephyr/dts/arm/infineon/cat1b/psc3/psc3_s.dtsi:294 */
					status = "disabled";                   /* in zephyr/dts/arm/infineon/cat1b/psc3/psc3_s.dtsi:295 */
				};
			};
		};

		/* node '/soc/tcpwm1@52a10000' defined in zephyr/dts/arm/infineon/cat1b/psc3/psc3_s.dtsi:300 */
		tcpwm1: tcpwm1@52a10000 {
			reg = < 0x52a10000 0x10000 >; /* in zephyr/dts/arm/infineon/cat1b/psc3/psc3_s.dtsi:301 */
			#address-cells = < 0x1 >;     /* in zephyr/dts/arm/infineon/cat1b/psc3/psc3_s.dtsi:302 */
			#size-cells = < 0x1 >;        /* in zephyr/dts/arm/infineon/cat1b/psc3/psc3_s.dtsi:303 */

			/* node '/soc/tcpwm1@52a10000/tcpwm1_0@52a10000' defined in zephyr/dts/arm/infineon/cat1b/psc3/psc3_s.dtsi:305 */
			tcpwm1_0: tcpwm1_0@52a10000 {
				compatible = "infineon,tcpwm"; /* in zephyr/dts/arm/infineon/cat1b/psc3/psc3_s.dtsi:306 */
				reg = < 0x52a10000 0x100 >;    /* in zephyr/dts/arm/infineon/cat1b/psc3/psc3_s.dtsi:307 */
				interrupts = < 0x50 0x4 >;     /* in zephyr/dts/arm/infineon/cat1b/psc3/psc3_s.dtsi:308 */
				resolution = < 0x10 >;         /* in zephyr/dts/arm/infineon/cat1b/psc3/psc3_s.dtsi:309 */
				status = "disabled";           /* in zephyr/dts/arm/infineon/cat1b/psc3/psc3_s.dtsi:310 */

				/* node '/soc/tcpwm1@52a10000/tcpwm1_0@52a10000/pwm1_0' defined in zephyr/dts/arm/infineon/cat1b/psc3/psc3_s.dtsi:312 */
				pwm1_0: pwm1_0 {
					compatible = "infineon,tcpwm-pwm"; /* in zephyr/dts/arm/infineon/cat1b/psc3/psc3_s.dtsi:313 */
					#pwm-cells = < 0x3 >;              /* in zephyr/dts/arm/infineon/cat1b/psc3/psc3_s.dtsi:314 */
					status = "disabled";               /* in zephyr/dts/arm/infineon/cat1b/psc3/psc3_s.dtsi:315 */
				};

				/* node '/soc/tcpwm1@52a10000/tcpwm1_0@52a10000/counter1_0' defined in zephyr/dts/arm/infineon/cat1b/psc3/psc3_s.dtsi:318 */
				counter1_0: counter1_0 {
					compatible = "infineon,tcpwm-counter"; /* in zephyr/dts/arm/infineon/cat1b/psc3/psc3_s.dtsi:319 */
					status = "disabled";                   /* in zephyr/dts/arm/infineon/cat1b/psc3/psc3_s.dtsi:320 */
				};
			};

			/* node '/soc/tcpwm1@52a10000/tcpwm1_1@52a10100' defined in zephyr/dts/arm/infineon/cat1b/psc3/psc3_s.dtsi:324 */
			tcpwm1_1: tcpwm1_1@52a10100 {
				compatible = "infineon,tcpwm"; /* in zephyr/dts/arm/infineon/cat1b/psc3/psc3_s.dtsi:325 */
				reg = < 0x52a10100 0x100 >;    /* in zephyr/dts/arm/infineon/cat1b/psc3/psc3_s.dtsi:326 */
				interrupts = < 0x51 0x4 >;     /* in zephyr/dts/arm/infineon/cat1b/psc3/psc3_s.dtsi:327 */
				resolution = < 0x10 >;         /* in zephyr/dts/arm/infineon/cat1b/psc3/psc3_s.dtsi:328 */
				status = "disabled";           /* in zephyr/dts/arm/infineon/cat1b/psc3/psc3_s.dtsi:329 */

				/* node '/soc/tcpwm1@52a10000/tcpwm1_1@52a10100/pwm1_1' defined in zephyr/dts/arm/infineon/cat1b/psc3/psc3_s.dtsi:331 */
				pwm1_1: pwm1_1 {
					compatible = "infineon,tcpwm-pwm"; /* in zephyr/dts/arm/infineon/cat1b/psc3/psc3_s.dtsi:332 */
					#pwm-cells = < 0x3 >;              /* in zephyr/dts/arm/infineon/cat1b/psc3/psc3_s.dtsi:333 */
					status = "disabled";               /* in zephyr/dts/arm/infineon/cat1b/psc3/psc3_s.dtsi:334 */
				};

				/* node '/soc/tcpwm1@52a10000/tcpwm1_1@52a10100/counter1_1' defined in zephyr/dts/arm/infineon/cat1b/psc3/psc3_s.dtsi:337 */
				counter1_1: counter1_1 {
					compatible = "infineon,tcpwm-counter"; /* in zephyr/dts/arm/infineon/cat1b/psc3/psc3_s.dtsi:338 */
					status = "disabled";                   /* in zephyr/dts/arm/infineon/cat1b/psc3/psc3_s.dtsi:339 */
				};
			};

			/* node '/soc/tcpwm1@52a10000/tcpwm1_2@52a10200' defined in zephyr/dts/arm/infineon/cat1b/psc3/psc3_s.dtsi:343 */
			tcpwm1_2: tcpwm1_2@52a10200 {
				compatible = "infineon,tcpwm"; /* in zephyr/dts/arm/infineon/cat1b/psc3/psc3_s.dtsi:344 */
				reg = < 0x52a10200 0x100 >;    /* in zephyr/dts/arm/infineon/cat1b/psc3/psc3_s.dtsi:345 */
				interrupts = < 0x52 0x4 >;     /* in zephyr/dts/arm/infineon/cat1b/psc3/psc3_s.dtsi:346 */
				resolution = < 0x10 >;         /* in zephyr/dts/arm/infineon/cat1b/psc3/psc3_s.dtsi:347 */
				status = "disabled";           /* in zephyr/dts/arm/infineon/cat1b/psc3/psc3_s.dtsi:348 */

				/* node '/soc/tcpwm1@52a10000/tcpwm1_2@52a10200/pwm1_2' defined in zephyr/dts/arm/infineon/cat1b/psc3/psc3_s.dtsi:350 */
				pwm1_2: pwm1_2 {
					compatible = "infineon,tcpwm-pwm"; /* in zephyr/dts/arm/infineon/cat1b/psc3/psc3_s.dtsi:351 */
					#pwm-cells = < 0x3 >;              /* in zephyr/dts/arm/infineon/cat1b/psc3/psc3_s.dtsi:352 */
					status = "disabled";               /* in zephyr/dts/arm/infineon/cat1b/psc3/psc3_s.dtsi:353 */
				};

				/* node '/soc/tcpwm1@52a10000/tcpwm1_2@52a10200/counter1_2' defined in zephyr/dts/arm/infineon/cat1b/psc3/psc3_s.dtsi:356 */
				counter1_2: counter1_2 {
					compatible = "infineon,tcpwm-counter"; /* in zephyr/dts/arm/infineon/cat1b/psc3/psc3_s.dtsi:357 */
					status = "disabled";                   /* in zephyr/dts/arm/infineon/cat1b/psc3/psc3_s.dtsi:358 */
				};
			};

			/* node '/soc/tcpwm1@52a10000/tcpwm1_3@52a10300' defined in zephyr/dts/arm/infineon/cat1b/psc3/psc3_s.dtsi:362 */
			tcpwm1_3: tcpwm1_3@52a10300 {
				compatible = "infineon,tcpwm"; /* in zephyr/dts/arm/infineon/cat1b/psc3/psc3_s.dtsi:363 */
				reg = < 0x52a10300 0x100 >;    /* in zephyr/dts/arm/infineon/cat1b/psc3/psc3_s.dtsi:364 */
				interrupts = < 0x53 0x4 >;     /* in zephyr/dts/arm/infineon/cat1b/psc3/psc3_s.dtsi:365 */
				resolution = < 0x10 >;         /* in zephyr/dts/arm/infineon/cat1b/psc3/psc3_s.dtsi:366 */
				status = "disabled";           /* in zephyr/dts/arm/infineon/cat1b/psc3/psc3_s.dtsi:367 */

				/* node '/soc/tcpwm1@52a10000/tcpwm1_3@52a10300/pwm1_3' defined in zephyr/dts/arm/infineon/cat1b/psc3/psc3_s.dtsi:369 */
				pwm1_3: pwm1_3 {
					compatible = "infineon,tcpwm-pwm"; /* in zephyr/dts/arm/infineon/cat1b/psc3/psc3_s.dtsi:370 */
					#pwm-cells = < 0x3 >;              /* in zephyr/dts/arm/infineon/cat1b/psc3/psc3_s.dtsi:371 */
					status = "disabled";               /* in zephyr/dts/arm/infineon/cat1b/psc3/psc3_s.dtsi:372 */
				};

				/* node '/soc/tcpwm1@52a10000/tcpwm1_3@52a10300/counter1_3' defined in zephyr/dts/arm/infineon/cat1b/psc3/psc3_s.dtsi:375 */
				counter1_3: counter1_3 {
					compatible = "infineon,tcpwm-counter"; /* in zephyr/dts/arm/infineon/cat1b/psc3/psc3_s.dtsi:376 */
					status = "disabled";                   /* in zephyr/dts/arm/infineon/cat1b/psc3/psc3_s.dtsi:377 */
				};
			};

			/* node '/soc/tcpwm1@52a10000/tcpwm1_4@52a10400' defined in zephyr/dts/arm/infineon/cat1b/psc3/psc3_s.dtsi:381 */
			tcpwm1_4: tcpwm1_4@52a10400 {
				compatible = "infineon,tcpwm"; /* in zephyr/dts/arm/infineon/cat1b/psc3/psc3_s.dtsi:382 */
				reg = < 0x52a10400 0x100 >;    /* in zephyr/dts/arm/infineon/cat1b/psc3/psc3_s.dtsi:383 */
				interrupts = < 0x54 0x4 >;     /* in zephyr/dts/arm/infineon/cat1b/psc3/psc3_s.dtsi:384 */
				resolution = < 0x10 >;         /* in zephyr/dts/arm/infineon/cat1b/psc3/psc3_s.dtsi:385 */
				status = "disabled";           /* in zephyr/dts/arm/infineon/cat1b/psc3/psc3_s.dtsi:386 */

				/* node '/soc/tcpwm1@52a10000/tcpwm1_4@52a10400/pwm1_4' defined in zephyr/dts/arm/infineon/cat1b/psc3/psc3_s.dtsi:388 */
				pwm1_4: pwm1_4 {
					compatible = "infineon,tcpwm-pwm"; /* in zephyr/dts/arm/infineon/cat1b/psc3/psc3_s.dtsi:389 */
					#pwm-cells = < 0x3 >;              /* in zephyr/dts/arm/infineon/cat1b/psc3/psc3_s.dtsi:390 */
					status = "disabled";               /* in zephyr/dts/arm/infineon/cat1b/psc3/psc3_s.dtsi:391 */
				};

				/* node '/soc/tcpwm1@52a10000/tcpwm1_4@52a10400/counter1_4' defined in zephyr/dts/arm/infineon/cat1b/psc3/psc3_s.dtsi:394 */
				counter1_4: counter1_4 {
					compatible = "infineon,tcpwm-counter"; /* in zephyr/dts/arm/infineon/cat1b/psc3/psc3_s.dtsi:395 */
					status = "disabled";                   /* in zephyr/dts/arm/infineon/cat1b/psc3/psc3_s.dtsi:396 */
				};
			};

			/* node '/soc/tcpwm1@52a10000/tcpwm1_5@52a10500' defined in zephyr/dts/arm/infineon/cat1b/psc3/psc3_s.dtsi:400 */
			tcpwm1_5: tcpwm1_5@52a10500 {
				compatible = "infineon,tcpwm"; /* in zephyr/dts/arm/infineon/cat1b/psc3/psc3_s.dtsi:401 */
				reg = < 0x52a10500 0x100 >;    /* in zephyr/dts/arm/infineon/cat1b/psc3/psc3_s.dtsi:402 */
				interrupts = < 0x55 0x4 >;     /* in zephyr/dts/arm/infineon/cat1b/psc3/psc3_s.dtsi:403 */
				resolution = < 0x10 >;         /* in zephyr/dts/arm/infineon/cat1b/psc3/psc3_s.dtsi:404 */
				status = "disabled";           /* in zephyr/dts/arm/infineon/cat1b/psc3/psc3_s.dtsi:405 */

				/* node '/soc/tcpwm1@52a10000/tcpwm1_5@52a10500/pwm1_5' defined in zephyr/dts/arm/infineon/cat1b/psc3/psc3_s.dtsi:407 */
				pwm1_5: pwm1_5 {
					compatible = "infineon,tcpwm-pwm"; /* in zephyr/dts/arm/infineon/cat1b/psc3/psc3_s.dtsi:408 */
					#pwm-cells = < 0x3 >;              /* in zephyr/dts/arm/infineon/cat1b/psc3/psc3_s.dtsi:409 */
					status = "disabled";               /* in zephyr/dts/arm/infineon/cat1b/psc3/psc3_s.dtsi:410 */
				};

				/* node '/soc/tcpwm1@52a10000/tcpwm1_5@52a10500/counter1_5' defined in zephyr/dts/arm/infineon/cat1b/psc3/psc3_s.dtsi:413 */
				counter1_5: counter1_5 {
					compatible = "infineon,tcpwm-counter"; /* in zephyr/dts/arm/infineon/cat1b/psc3/psc3_s.dtsi:414 */
					status = "disabled";                   /* in zephyr/dts/arm/infineon/cat1b/psc3/psc3_s.dtsi:415 */
				};
			};

			/* node '/soc/tcpwm1@52a10000/tcpwm1_6@52a10600' defined in zephyr/dts/arm/infineon/cat1b/psc3/psc3_s.dtsi:419 */
			tcpwm1_6: tcpwm1_6@52a10600 {
				compatible = "infineon,tcpwm"; /* in zephyr/dts/arm/infineon/cat1b/psc3/psc3_s.dtsi:420 */
				reg = < 0x52a10600 0x100 >;    /* in zephyr/dts/arm/infineon/cat1b/psc3/psc3_s.dtsi:421 */
				interrupts = < 0x56 0x4 >;     /* in zephyr/dts/arm/infineon/cat1b/psc3/psc3_s.dtsi:422 */
				resolution = < 0x10 >;         /* in zephyr/dts/arm/infineon/cat1b/psc3/psc3_s.dtsi:423 */
				status = "disabled";           /* in zephyr/dts/arm/infineon/cat1b/psc3/psc3_s.dtsi:424 */

				/* node '/soc/tcpwm1@52a10000/tcpwm1_6@52a10600/pwm1_6' defined in zephyr/dts/arm/infineon/cat1b/psc3/psc3_s.dtsi:426 */
				pwm1_6: pwm1_6 {
					compatible = "infineon,tcpwm-pwm"; /* in zephyr/dts/arm/infineon/cat1b/psc3/psc3_s.dtsi:427 */
					#pwm-cells = < 0x3 >;              /* in zephyr/dts/arm/infineon/cat1b/psc3/psc3_s.dtsi:428 */
					status = "disabled";               /* in zephyr/dts/arm/infineon/cat1b/psc3/psc3_s.dtsi:429 */
				};

				/* node '/soc/tcpwm1@52a10000/tcpwm1_6@52a10600/counter1_6' defined in zephyr/dts/arm/infineon/cat1b/psc3/psc3_s.dtsi:432 */
				counter1_6: counter1_6 {
					compatible = "infineon,tcpwm-counter"; /* in zephyr/dts/arm/infineon/cat1b/psc3/psc3_s.dtsi:433 */
					status = "disabled";                   /* in zephyr/dts/arm/infineon/cat1b/psc3/psc3_s.dtsi:434 */
				};
			};

			/* node '/soc/tcpwm1@52a10000/tcpwm1_7@52a10700' defined in zephyr/dts/arm/infineon/cat1b/psc3/psc3_s.dtsi:438 */
			tcpwm1_7: tcpwm1_7@52a10700 {
				compatible = "infineon,tcpwm"; /* in zephyr/dts/arm/infineon/cat1b/psc3/psc3_s.dtsi:439 */
				reg = < 0x52a10700 0x100 >;    /* in zephyr/dts/arm/infineon/cat1b/psc3/psc3_s.dtsi:440 */
				interrupts = < 0x57 0x4 >;     /* in zephyr/dts/arm/infineon/cat1b/psc3/psc3_s.dtsi:441 */
				resolution = < 0x10 >;         /* in zephyr/dts/arm/infineon/cat1b/psc3/psc3_s.dtsi:442 */
				status = "disabled";           /* in zephyr/dts/arm/infineon/cat1b/psc3/psc3_s.dtsi:443 */

				/* node '/soc/tcpwm1@52a10000/tcpwm1_7@52a10700/pwm1_7' defined in zephyr/dts/arm/infineon/cat1b/psc3/psc3_s.dtsi:445 */
				pwm1_7: pwm1_7 {
					compatible = "infineon,tcpwm-pwm"; /* in zephyr/dts/arm/infineon/cat1b/psc3/psc3_s.dtsi:446 */
					#pwm-cells = < 0x3 >;              /* in zephyr/dts/arm/infineon/cat1b/psc3/psc3_s.dtsi:447 */
					status = "disabled";               /* in zephyr/dts/arm/infineon/cat1b/psc3/psc3_s.dtsi:448 */
				};

				/* node '/soc/tcpwm1@52a10000/tcpwm1_7@52a10700/counter1_7' defined in zephyr/dts/arm/infineon/cat1b/psc3/psc3_s.dtsi:451 */
				counter1_7: counter1_7 {
					compatible = "infineon,tcpwm-counter"; /* in zephyr/dts/arm/infineon/cat1b/psc3/psc3_s.dtsi:452 */
					status = "disabled";                   /* in zephyr/dts/arm/infineon/cat1b/psc3/psc3_s.dtsi:453 */
				};
			};
		};

		/* node '/soc/tcpwm2@52a20000' defined in zephyr/dts/arm/infineon/cat1b/psc3/psc3_s.dtsi:458 */
		tcpwm2: tcpwm2@52a20000 {
			reg = < 0x52a20000 0x10000 >; /* in zephyr/dts/arm/infineon/cat1b/psc3/psc3_s.dtsi:459 */
			#address-cells = < 0x1 >;     /* in zephyr/dts/arm/infineon/cat1b/psc3/psc3_s.dtsi:460 */
			#size-cells = < 0x1 >;        /* in zephyr/dts/arm/infineon/cat1b/psc3/psc3_s.dtsi:461 */

			/* node '/soc/tcpwm2@52a20000/tcpwm2_0@52a20000' defined in zephyr/dts/arm/infineon/cat1b/psc3/psc3_s.dtsi:463 */
			tcpwm2_0: tcpwm2_0@52a20000 {
				compatible = "infineon,tcpwm"; /* in zephyr/dts/arm/infineon/cat1b/psc3/psc3_s.dtsi:464 */
				reg = < 0x52a20000 0x100 >;    /* in zephyr/dts/arm/infineon/cat1b/psc3/psc3_s.dtsi:465 */
				interrupts = < 0x58 0x4 >;     /* in zephyr/dts/arm/infineon/cat1b/psc3/psc3_s.dtsi:466 */
				resolution = < 0x10 >;         /* in zephyr/dts/arm/infineon/cat1b/psc3/psc3_s.dtsi:467 */
				status = "disabled";           /* in zephyr/dts/arm/infineon/cat1b/psc3/psc3_s.dtsi:468 */

				/* node '/soc/tcpwm2@52a20000/tcpwm2_0@52a20000/pwm2_0' defined in zephyr/dts/arm/infineon/cat1b/psc3/psc3_s.dtsi:470 */
				pwm2_0: pwm2_0 {
					compatible = "infineon,tcpwm-pwm"; /* in zephyr/dts/arm/infineon/cat1b/psc3/psc3_s.dtsi:471 */
					#pwm-cells = < 0x3 >;              /* in zephyr/dts/arm/infineon/cat1b/psc3/psc3_s.dtsi:472 */
					status = "disabled";               /* in zephyr/dts/arm/infineon/cat1b/psc3/psc3_s.dtsi:473 */
				};

				/* node '/soc/tcpwm2@52a20000/tcpwm2_0@52a20000/counter2_0' defined in zephyr/dts/arm/infineon/cat1b/psc3/psc3_s.dtsi:476 */
				counter2_0: counter2_0 {
					compatible = "infineon,tcpwm-counter"; /* in zephyr/dts/arm/infineon/cat1b/psc3/psc3_s.dtsi:477 */
					status = "disabled";                   /* in zephyr/dts/arm/infineon/cat1b/psc3/psc3_s.dtsi:478 */
				};
			};

			/* node '/soc/tcpwm2@52a20000/tcpwm2_1@52a20100' defined in zephyr/dts/arm/infineon/cat1b/psc3/psc3_s.dtsi:482 */
			tcpwm2_1: tcpwm2_1@52a20100 {
				compatible = "infineon,tcpwm"; /* in zephyr/dts/arm/infineon/cat1b/psc3/psc3_s.dtsi:483 */
				reg = < 0x52a20100 0x100 >;    /* in zephyr/dts/arm/infineon/cat1b/psc3/psc3_s.dtsi:484 */
				interrupts = < 0x59 0x4 >;     /* in zephyr/dts/arm/infineon/cat1b/psc3/psc3_s.dtsi:485 */
				resolution = < 0x10 >;         /* in zephyr/dts/arm/infineon/cat1b/psc3/psc3_s.dtsi:486 */
				status = "disabled";           /* in zephyr/dts/arm/infineon/cat1b/psc3/psc3_s.dtsi:487 */

				/* node '/soc/tcpwm2@52a20000/tcpwm2_1@52a20100/pwm2_1' defined in zephyr/dts/arm/infineon/cat1b/psc3/psc3_s.dtsi:489 */
				pwm2_1: pwm2_1 {
					compatible = "infineon,tcpwm-pwm"; /* in zephyr/dts/arm/infineon/cat1b/psc3/psc3_s.dtsi:490 */
					#pwm-cells = < 0x3 >;              /* in zephyr/dts/arm/infineon/cat1b/psc3/psc3_s.dtsi:491 */
					status = "disabled";               /* in zephyr/dts/arm/infineon/cat1b/psc3/psc3_s.dtsi:492 */
				};

				/* node '/soc/tcpwm2@52a20000/tcpwm2_1@52a20100/counter2_1' defined in zephyr/dts/arm/infineon/cat1b/psc3/psc3_s.dtsi:495 */
				counter2_1: counter2_1 {
					compatible = "infineon,tcpwm-counter"; /* in zephyr/dts/arm/infineon/cat1b/psc3/psc3_s.dtsi:496 */
					status = "disabled";                   /* in zephyr/dts/arm/infineon/cat1b/psc3/psc3_s.dtsi:497 */
				};
			};

			/* node '/soc/tcpwm2@52a20000/tcpwm2_2@52a20200' defined in zephyr/dts/arm/infineon/cat1b/psc3/psc3_s.dtsi:501 */
			tcpwm2_2: tcpwm2_2@52a20200 {
				compatible = "infineon,tcpwm"; /* in zephyr/dts/arm/infineon/cat1b/psc3/psc3_s.dtsi:502 */
				reg = < 0x52a20200 0x100 >;    /* in zephyr/dts/arm/infineon/cat1b/psc3/psc3_s.dtsi:503 */
				interrupts = < 0x5a 0x4 >;     /* in zephyr/dts/arm/infineon/cat1b/psc3/psc3_s.dtsi:504 */
				resolution = < 0x10 >;         /* in zephyr/dts/arm/infineon/cat1b/psc3/psc3_s.dtsi:505 */
				status = "disabled";           /* in zephyr/dts/arm/infineon/cat1b/psc3/psc3_s.dtsi:506 */

				/* node '/soc/tcpwm2@52a20000/tcpwm2_2@52a20200/pwm2_2' defined in zephyr/dts/arm/infineon/cat1b/psc3/psc3_s.dtsi:508 */
				pwm2_2: pwm2_2 {
					compatible = "infineon,tcpwm-pwm"; /* in zephyr/dts/arm/infineon/cat1b/psc3/psc3_s.dtsi:509 */
					#pwm-cells = < 0x3 >;              /* in zephyr/dts/arm/infineon/cat1b/psc3/psc3_s.dtsi:510 */
					status = "disabled";               /* in zephyr/dts/arm/infineon/cat1b/psc3/psc3_s.dtsi:511 */
				};

				/* node '/soc/tcpwm2@52a20000/tcpwm2_2@52a20200/counter2_2' defined in zephyr/dts/arm/infineon/cat1b/psc3/psc3_s.dtsi:514 */
				counter2_2: counter2_2 {
					compatible = "infineon,tcpwm-counter"; /* in zephyr/dts/arm/infineon/cat1b/psc3/psc3_s.dtsi:515 */
					status = "disabled";                   /* in zephyr/dts/arm/infineon/cat1b/psc3/psc3_s.dtsi:516 */
				};
			};

			/* node '/soc/tcpwm2@52a20000/tcpwm2_3@52a20300' defined in zephyr/dts/arm/infineon/cat1b/psc3/psc3_s.dtsi:520 */
			tcpwm2_3: tcpwm2_3@52a20300 {
				compatible = "infineon,tcpwm"; /* in zephyr/dts/arm/infineon/cat1b/psc3/psc3_s.dtsi:521 */
				reg = < 0x52a20300 0x100 >;    /* in zephyr/dts/arm/infineon/cat1b/psc3/psc3_s.dtsi:522 */
				interrupts = < 0x5b 0x4 >;     /* in zephyr/dts/arm/infineon/cat1b/psc3/psc3_s.dtsi:523 */
				resolution = < 0x10 >;         /* in zephyr/dts/arm/infineon/cat1b/psc3/psc3_s.dtsi:524 */
				status = "disabled";           /* in zephyr/dts/arm/infineon/cat1b/psc3/psc3_s.dtsi:525 */

				/* node '/soc/tcpwm2@52a20000/tcpwm2_3@52a20300/pwm2_3' defined in zephyr/dts/arm/infineon/cat1b/psc3/psc3_s.dtsi:527 */
				pwm2_3: pwm2_3 {
					compatible = "infineon,tcpwm-pwm"; /* in zephyr/dts/arm/infineon/cat1b/psc3/psc3_s.dtsi:528 */
					#pwm-cells = < 0x3 >;              /* in zephyr/dts/arm/infineon/cat1b/psc3/psc3_s.dtsi:529 */
					status = "disabled";               /* in zephyr/dts/arm/infineon/cat1b/psc3/psc3_s.dtsi:530 */
				};

				/* node '/soc/tcpwm2@52a20000/tcpwm2_3@52a20300/counter2_3' defined in zephyr/dts/arm/infineon/cat1b/psc3/psc3_s.dtsi:533 */
				counter2_3: counter2_3 {
					compatible = "infineon,tcpwm-counter"; /* in zephyr/dts/arm/infineon/cat1b/psc3/psc3_s.dtsi:534 */
					status = "disabled";                   /* in zephyr/dts/arm/infineon/cat1b/psc3/psc3_s.dtsi:535 */
				};
			};

			/* node '/soc/tcpwm2@52a20000/tcpwm2_4@52a20400' defined in zephyr/dts/arm/infineon/cat1b/psc3/psc3_s.dtsi:539 */
			tcpwm2_4: tcpwm2_4@52a20400 {
				compatible = "infineon,tcpwm"; /* in zephyr/dts/arm/infineon/cat1b/psc3/psc3_s.dtsi:540 */
				reg = < 0x52a20400 0x100 >;    /* in zephyr/dts/arm/infineon/cat1b/psc3/psc3_s.dtsi:541 */
				interrupts = < 0x5c 0x4 >;     /* in zephyr/dts/arm/infineon/cat1b/psc3/psc3_s.dtsi:542 */
				resolution = < 0x10 >;         /* in zephyr/dts/arm/infineon/cat1b/psc3/psc3_s.dtsi:543 */
				status = "disabled";           /* in zephyr/dts/arm/infineon/cat1b/psc3/psc3_s.dtsi:544 */

				/* node '/soc/tcpwm2@52a20000/tcpwm2_4@52a20400/pwm2_4' defined in zephyr/dts/arm/infineon/cat1b/psc3/psc3_s.dtsi:546 */
				pwm2_4: pwm2_4 {
					compatible = "infineon,tcpwm-pwm"; /* in zephyr/dts/arm/infineon/cat1b/psc3/psc3_s.dtsi:547 */
					#pwm-cells = < 0x3 >;              /* in zephyr/dts/arm/infineon/cat1b/psc3/psc3_s.dtsi:548 */
					status = "disabled";               /* in zephyr/dts/arm/infineon/cat1b/psc3/psc3_s.dtsi:549 */
				};

				/* node '/soc/tcpwm2@52a20000/tcpwm2_4@52a20400/counter2_4' defined in zephyr/dts/arm/infineon/cat1b/psc3/psc3_s.dtsi:552 */
				counter2_4: counter2_4 {
					compatible = "infineon,tcpwm-counter"; /* in zephyr/dts/arm/infineon/cat1b/psc3/psc3_s.dtsi:553 */
					status = "disabled";                   /* in zephyr/dts/arm/infineon/cat1b/psc3/psc3_s.dtsi:554 */
				};
			};

			/* node '/soc/tcpwm2@52a20000/tcpwm2_5@52a20500' defined in zephyr/dts/arm/infineon/cat1b/psc3/psc3_s.dtsi:558 */
			tcpwm2_5: tcpwm2_5@52a20500 {
				compatible = "infineon,tcpwm"; /* in zephyr/dts/arm/infineon/cat1b/psc3/psc3_s.dtsi:559 */
				reg = < 0x52a20500 0x100 >;    /* in zephyr/dts/arm/infineon/cat1b/psc3/psc3_s.dtsi:560 */
				interrupts = < 0x5d 0x4 >;     /* in zephyr/dts/arm/infineon/cat1b/psc3/psc3_s.dtsi:561 */
				resolution = < 0x10 >;         /* in zephyr/dts/arm/infineon/cat1b/psc3/psc3_s.dtsi:562 */
				status = "disabled";           /* in zephyr/dts/arm/infineon/cat1b/psc3/psc3_s.dtsi:563 */

				/* node '/soc/tcpwm2@52a20000/tcpwm2_5@52a20500/pwm2_5' defined in zephyr/dts/arm/infineon/cat1b/psc3/psc3_s.dtsi:565 */
				pwm2_5: pwm2_5 {
					compatible = "infineon,tcpwm-pwm"; /* in zephyr/dts/arm/infineon/cat1b/psc3/psc3_s.dtsi:566 */
					#pwm-cells = < 0x3 >;              /* in zephyr/dts/arm/infineon/cat1b/psc3/psc3_s.dtsi:567 */
					status = "disabled";               /* in zephyr/dts/arm/infineon/cat1b/psc3/psc3_s.dtsi:568 */
				};

				/* node '/soc/tcpwm2@52a20000/tcpwm2_5@52a20500/counter2_5' defined in zephyr/dts/arm/infineon/cat1b/psc3/psc3_s.dtsi:571 */
				counter2_5: counter2_5 {
					compatible = "infineon,tcpwm-counter"; /* in zephyr/dts/arm/infineon/cat1b/psc3/psc3_s.dtsi:572 */
					status = "disabled";                   /* in zephyr/dts/arm/infineon/cat1b/psc3/psc3_s.dtsi:573 */
				};
			};

			/* node '/soc/tcpwm2@52a20000/tcpwm2_6@52a20600' defined in zephyr/dts/arm/infineon/cat1b/psc3/psc3_s.dtsi:577 */
			tcpwm2_6: tcpwm2_6@52a20600 {
				compatible = "infineon,tcpwm"; /* in zephyr/dts/arm/infineon/cat1b/psc3/psc3_s.dtsi:578 */
				reg = < 0x52a20600 0x100 >;    /* in zephyr/dts/arm/infineon/cat1b/psc3/psc3_s.dtsi:579 */
				interrupts = < 0x5e 0x4 >;     /* in zephyr/dts/arm/infineon/cat1b/psc3/psc3_s.dtsi:580 */
				resolution = < 0x10 >;         /* in zephyr/dts/arm/infineon/cat1b/psc3/psc3_s.dtsi:581 */
				status = "disabled";           /* in zephyr/dts/arm/infineon/cat1b/psc3/psc3_s.dtsi:582 */

				/* node '/soc/tcpwm2@52a20000/tcpwm2_6@52a20600/pwm2_6' defined in zephyr/dts/arm/infineon/cat1b/psc3/psc3_s.dtsi:584 */
				pwm2_6: pwm2_6 {
					compatible = "infineon,tcpwm-pwm"; /* in zephyr/dts/arm/infineon/cat1b/psc3/psc3_s.dtsi:585 */
					#pwm-cells = < 0x3 >;              /* in zephyr/dts/arm/infineon/cat1b/psc3/psc3_s.dtsi:586 */
					status = "disabled";               /* in zephyr/dts/arm/infineon/cat1b/psc3/psc3_s.dtsi:587 */
				};

				/* node '/soc/tcpwm2@52a20000/tcpwm2_6@52a20600/counter2_6' defined in zephyr/dts/arm/infineon/cat1b/psc3/psc3_s.dtsi:590 */
				counter2_6: counter2_6 {
					compatible = "infineon,tcpwm-counter"; /* in zephyr/dts/arm/infineon/cat1b/psc3/psc3_s.dtsi:591 */
					status = "disabled";                   /* in zephyr/dts/arm/infineon/cat1b/psc3/psc3_s.dtsi:592 */
				};
			};

			/* node '/soc/tcpwm2@52a20000/tcpwm2_7@52a20700' defined in zephyr/dts/arm/infineon/cat1b/psc3/psc3_s.dtsi:596 */
			tcpwm2_7: tcpwm2_7@52a20700 {
				compatible = "infineon,tcpwm"; /* in zephyr/dts/arm/infineon/cat1b/psc3/psc3_s.dtsi:597 */
				reg = < 0x52a20700 0x100 >;    /* in zephyr/dts/arm/infineon/cat1b/psc3/psc3_s.dtsi:598 */
				interrupts = < 0x5f 0x4 >;     /* in zephyr/dts/arm/infineon/cat1b/psc3/psc3_s.dtsi:599 */
				resolution = < 0x10 >;         /* in zephyr/dts/arm/infineon/cat1b/psc3/psc3_s.dtsi:600 */
				status = "disabled";           /* in zephyr/dts/arm/infineon/cat1b/psc3/psc3_s.dtsi:601 */

				/* node '/soc/tcpwm2@52a20000/tcpwm2_7@52a20700/pwm2_7' defined in zephyr/dts/arm/infineon/cat1b/psc3/psc3_s.dtsi:603 */
				pwm2_7: pwm2_7 {
					compatible = "infineon,tcpwm-pwm"; /* in zephyr/dts/arm/infineon/cat1b/psc3/psc3_s.dtsi:604 */
					#pwm-cells = < 0x3 >;              /* in zephyr/dts/arm/infineon/cat1b/psc3/psc3_s.dtsi:605 */
					status = "disabled";               /* in zephyr/dts/arm/infineon/cat1b/psc3/psc3_s.dtsi:606 */
				};

				/* node '/soc/tcpwm2@52a20000/tcpwm2_7@52a20700/counter2_7' defined in zephyr/dts/arm/infineon/cat1b/psc3/psc3_s.dtsi:609 */
				counter2_7: counter2_7 {
					compatible = "infineon,tcpwm-counter"; /* in zephyr/dts/arm/infineon/cat1b/psc3/psc3_s.dtsi:610 */
					status = "disabled";                   /* in zephyr/dts/arm/infineon/cat1b/psc3/psc3_s.dtsi:611 */
				};
			};
		};

		/* node '/soc/dw@52180000' defined in zephyr/dts/arm/infineon/cat1b/psc3/psc3_s.dtsi:616 */
		dma0: dw@52180000 {
			#dma-cells = < 0x1 >;             /* in zephyr/dts/arm/infineon/cat1b/psc3/psc3_s.dtsi:617 */
			compatible = "infineon,cat1-dma"; /* in zephyr/dts/arm/infineon/cat1b/psc3/psc3_s.dtsi:618 */
			reg = < 0x52180000 0x10000 >;     /* in zephyr/dts/arm/infineon/cat1b/psc3/psc3_s.dtsi:619 */
			dma-channels = < 0x10 >;          /* in zephyr/dts/arm/infineon/cat1b/psc3/psc3_s.dtsi:620 */
			interrupts = < 0x25 0x4 >,
			             < 0x26 0x4 >,
			             < 0x27 0x4 >,
			             < 0x28 0x4 >,
			             < 0x29 0x4 >,
			             < 0x2a 0x4 >,
			             < 0x2b 0x4 >,
			             < 0x2c 0x4 >,
			             < 0x2d 0x4 >,
			             < 0x2e 0x4 >,
			             < 0x2f 0x4 >,
			             < 0x30 0x4 >,
			             < 0x31 0x4 >,
			             < 0x32 0x4 >,
			             < 0x33 0x4 >,
			             < 0x34 0x4 >;        /* in zephyr/dts/arm/infineon/cat1b/psc3/psc3_s.dtsi:621 */
			status = "disabled";              /* in zephyr/dts/arm/infineon/cat1b/psc3/psc3_s.dtsi:637 */
		};

		/* node '/soc/dw@52190000' defined in zephyr/dts/arm/infineon/cat1b/psc3/psc3_s.dtsi:640 */
		dma1: dw@52190000 {
			#dma-cells = < 0x1 >;             /* in zephyr/dts/arm/infineon/cat1b/psc3/psc3_s.dtsi:641 */
			compatible = "infineon,cat1-dma"; /* in zephyr/dts/arm/infineon/cat1b/psc3/psc3_s.dtsi:642 */
			reg = < 0x52190000 0x10000 >;     /* in zephyr/dts/arm/infineon/cat1b/psc3/psc3_s.dtsi:643 */
			dma-channels = < 0x10 >;          /* in zephyr/dts/arm/infineon/cat1b/psc3/psc3_s.dtsi:644 */
			interrupts = < 0x35 0x4 >,
			             < 0x36 0x4 >,
			             < 0x37 0x4 >,
			             < 0x38 0x4 >,
			             < 0x39 0x4 >,
			             < 0x3a 0x4 >,
			             < 0x3b 0x4 >,
			             < 0x3c 0x4 >,
			             < 0x3d 0x4 >,
			             < 0x3e 0x4 >,
			             < 0x3f 0x4 >,
			             < 0x40 0x4 >,
			             < 0x41 0x4 >,
			             < 0x42 0x4 >,
			             < 0x43 0x4 >,
			             < 0x44 0x4 >;        /* in zephyr/dts/arm/infineon/cat1b/psc3/psc3_s.dtsi:645 */
			status = "disabled";              /* in zephyr/dts/arm/infineon/cat1b/psc3/psc3_s.dtsi:661 */
		};
	};

	/* node '/cpus' defined in zephyr/dts/arm/infineon/cat1b/psc3/psc3.cm33.dtsi:12 */
	cpus {
		#address-cells = < 0x1 >; /* in zephyr/dts/arm/infineon/cat1b/psc3/psc3.cm33.dtsi:13 */
		#size-cells = < 0x0 >;    /* in zephyr/dts/arm/infineon/cat1b/psc3/psc3.cm33.dtsi:14 */

		/* node '/cpus/cpu@0' defined in zephyr/dts/arm/infineon/cat1b/psc3/psc3.cm33.dtsi:16 */
		cpu@0 {
			device_type = "cpu";             /* in zephyr/dts/arm/infineon/cat1b/psc3/psc3.cm33.dtsi:17 */
			compatible = "arm,cortex-m33";   /* in zephyr/dts/arm/infineon/cat1b/psc3/psc3.cm33.dtsi:18 */
			reg = < 0x0 >;                   /* in zephyr/dts/arm/infineon/cat1b/psc3/psc3.cm33.dtsi:19 */
			clock-frequency = < 0xaba9500 >; /* in zephyr/dts/arm/infineon/cat1b/psc3/psc3.cm33.dtsi:20 */
		};
	};

	/* node '/memory@34000000' defined in zephyr/dts/arm/infineon/cat1b/psc3/psc3_s.dtsi:13 */
	sram0: memory@34000000 {
		compatible = "mmio-sram";     /* in zephyr/dts/arm/infineon/cat1b/psc3/psc3_s.dtsi:14 */
		reg = < 0x34000000 0x10000 >; /* in zephyr/dts/arm/infineon/cat1b/psc3/psc3_s.dtsi:15 */
	};

	/* node '/flash-controller@52150000' defined in zephyr/dts/arm/infineon/cat1b/mpns/psc3m5fds2afq1_s.dtsi:12 */
	flash-controller@52150000 {
		compatible = "infineon,cat1-flash-controller"; /* in zephyr/dts/arm/infineon/cat1b/mpns/psc3m5fds2afq1_s.dtsi:13 */
		reg = < 0x52150000 0x10000 >;                  /* in zephyr/dts/arm/infineon/cat1b/mpns/psc3m5fds2afq1_s.dtsi:14 */
		#address-cells = < 0x1 >;                      /* in zephyr/dts/arm/infineon/cat1b/mpns/psc3m5fds2afq1_s.dtsi:15 */
		#size-cells = < 0x1 >;                         /* in zephyr/dts/arm/infineon/cat1b/mpns/psc3m5fds2afq1_s.dtsi:16 */

		/* node '/flash-controller@52150000/flash@12000000' defined in zephyr/dts/arm/infineon/cat1b/mpns/psc3m5fds2afq1_s.dtsi:18 */
		flash0: flash@12000000 {
			compatible = "soc-nv-flash";  /* in zephyr/dts/arm/infineon/cat1b/mpns/psc3m5fds2afq1_s.dtsi:19 */
			reg = < 0x12000000 0x40000 >; /* in zephyr/dts/arm/infineon/cat1b/mpns/psc3m5fds2afq1_s.dtsi:20 */
			write-block-size = < 0x200 >; /* in zephyr/dts/arm/infineon/cat1b/mpns/psc3m5fds2afq1_s.dtsi:21 */
			erase-block-size = < 0x200 >; /* in zephyr/dts/arm/infineon/cat1b/mpns/psc3m5fds2afq1_s.dtsi:22 */

			/* node '/flash-controller@52150000/flash@12000000/partitions' defined in zephyr/dts/arm/infineon/cat1b/psc3/psc3_partition.dtsi:28 */
			partitions {
				compatible = "fixed-partitions"; /* in zephyr/dts/arm/infineon/cat1b/psc3/psc3_partition.dtsi:29 */
				#address-cells = < 0x1 >;        /* in zephyr/dts/arm/infineon/cat1b/psc3/psc3_partition.dtsi:30 */
				#size-cells = < 0x1 >;           /* in zephyr/dts/arm/infineon/cat1b/psc3/psc3_partition.dtsi:31 */

				/* node '/flash-controller@52150000/flash@12000000/partitions/partition@12000000' defined in zephyr/dts/arm/infineon/cat1b/psc3/psc3_partition.dtsi:33 */
				slot0_partition: partition@12000000 {
					reg = < 0x12000000 0x20000 >; /* in zephyr/dts/arm/infineon/cat1b/psc3/psc3_partition.dtsi:34 */
				};

				/* node '/flash-controller@52150000/flash@12000000/partitions/partition@2010000' defined in zephyr/dts/arm/infineon/cat1b/psc3/psc3_partition.dtsi:37 */
				slot0_ns_partition: partition@2010000 {
					reg = < 0x2010000 0x20000 >; /* in zephyr/dts/arm/infineon/cat1b/psc3/psc3_partition.dtsi:38 */
				};
			};
		};
	};

	/* node '/srss_power' defined in zephyr/dts/arm/infineon/cat1b/psc3/system_clocks.dtsi:17 */
	srss_power: srss_power {
		#clock-cells = < 0x0 >;              /* in zephyr/dts/arm/infineon/cat1b/psc3/system_clocks.dtsi:18 */
		compatible = "infineon,cat1b-power"; /* in zephyr/dts/arm/infineon/cat1b/psc3/system_clocks.dtsi:19 */
		power-profile = "POWER_PROFILE_0";   /* in zephyr/dts/arm/infineon/cat1b/psc3/system_clocks.dtsi:20 */
		status = "okay";                     /* in zephyr/dts/arm/infineon/cat1b/psc3/system_clocks.dtsi:21 */
	};

	/* node '/clocks' defined in zephyr/dts/arm/infineon/cat1b/psc3/system_clocks.dtsi:24 */
	clocks {

		/* node '/clocks/clk_iho' defined in zephyr/dts/arm/infineon/cat1b/psc3/system_clocks.dtsi:26 */
		clk_iho: clk_iho {
			#clock-cells = < 0x0 >;              /* in zephyr/dts/arm/infineon/cat1b/psc3/system_clocks.dtsi:27 */
			compatible = "infineon,fixed-clock"; /* in zephyr/dts/arm/infineon/cat1b/psc3/system_clocks.dtsi:28 */
			clock-frequency = < 0x2dc6c00 >;     /* in zephyr/dts/arm/infineon/cat1b/psc3/system_clocks.dtsi:29 */
			system-clock = < 0x1 >;              /* in zephyr/dts/arm/infineon/cat1b/psc3/system_clocks.dtsi:30 */
			status = "okay";                     /* in zephyr/dts/arm/infineon/cat1b/psc3/system_clocks.dtsi:31 */
			phandle = < 0x7 >;                   /* in zephyr/dts/arm/infineon/cat1b/psc3/system_clocks.dtsi:56 */
		};

		/* node '/clocks/clk_imo' defined in zephyr/dts/arm/infineon/cat1b/psc3/system_clocks.dtsi:35 */
		clk_imo: clk_imo {
			#clock-cells = < 0x0 >;              /* in zephyr/dts/arm/infineon/cat1b/psc3/system_clocks.dtsi:36 */
			compatible = "infineon,fixed-clock"; /* in zephyr/dts/arm/infineon/cat1b/psc3/system_clocks.dtsi:37 */
			clock-frequency = < 0x7a1200 >;      /* in zephyr/dts/arm/infineon/cat1b/psc3/system_clocks.dtsi:38 */
			system-clock = < 0x2 >;              /* in zephyr/dts/arm/infineon/cat1b/psc3/system_clocks.dtsi:39 */
			status = "okay";                     /* in zephyr/dts/arm/infineon/cat1b/psc3/system_clocks.dtsi:40 */
		};

		/* node '/clocks/fll0' defined in zephyr/dts/arm/infineon/cat1b/psc3/system_clocks.dtsi:44 */
		fll0: fll0 {
			#clock-cells = < 0x0 >;              /* in zephyr/dts/arm/infineon/cat1b/psc3/system_clocks.dtsi:45 */
			compatible = "infineon,fixed-clock"; /* in zephyr/dts/arm/infineon/cat1b/psc3/system_clocks.dtsi:46 */
			clock-frequency = < 0x5b8d800 >;     /* in zephyr/dts/arm/infineon/cat1b/psc3/system_clocks.dtsi:47 */
			system-clock = < 0xc >;              /* in zephyr/dts/arm/infineon/cat1b/psc3/system_clocks.dtsi:48 */
			status = "okay";                     /* in zephyr/dts/arm/infineon/cat1b/psc3/system_clocks.dtsi:49 */
		};

		/* node '/clocks/path_mux0' defined in zephyr/dts/arm/infineon/cat1b/psc3/system_clocks.dtsi:53 */
		path_mux0: path_mux0 {
			#clock-cells = < 0x0 >;                     /* in zephyr/dts/arm/infineon/cat1b/psc3/system_clocks.dtsi:54 */
			compatible = "infineon,fixed-factor-clock"; /* in zephyr/dts/arm/infineon/cat1b/psc3/system_clocks.dtsi:55 */
			clocks = < &clk_iho >;                      /* in zephyr/dts/arm/infineon/cat1b/psc3/system_clocks.dtsi:56 */
			system-clock = < 0xb >;                     /* in zephyr/dts/arm/infineon/cat1b/psc3/system_clocks.dtsi:57 */
			instance = < 0x0 >;                         /* in zephyr/dts/arm/infineon/cat1b/psc3/system_clocks.dtsi:58 */
			source-path = < 0x6 >;                      /* in zephyr/dts/arm/infineon/cat1b/psc3/system_clocks.dtsi:59 */
			status = "okay";                            /* in zephyr/boards/infineon/kit_psc3m5_evk/kit_psc3m5_evk.dts:48 */
			phandle = < 0x9 >;                          /* in zephyr/dts/arm/infineon/cat1b/psc3/system_clocks.dtsi:123 */
		};

		/* node '/clocks/path_mux1' defined in zephyr/dts/arm/infineon/cat1b/psc3/system_clocks.dtsi:64 */
		path_mux1: path_mux1 {
			#clock-cells = < 0x0 >;                     /* in zephyr/dts/arm/infineon/cat1b/psc3/system_clocks.dtsi:65 */
			compatible = "infineon,fixed-factor-clock"; /* in zephyr/dts/arm/infineon/cat1b/psc3/system_clocks.dtsi:66 */
			clocks = < &clk_iho >;                      /* in zephyr/dts/arm/infineon/cat1b/psc3/system_clocks.dtsi:67 */
			system-clock = < 0xb >;                     /* in zephyr/dts/arm/infineon/cat1b/psc3/system_clocks.dtsi:68 */
			instance = < 0x1 >;                         /* in zephyr/dts/arm/infineon/cat1b/psc3/system_clocks.dtsi:69 */
			source-path = < 0x6 >;                      /* in zephyr/dts/arm/infineon/cat1b/psc3/system_clocks.dtsi:70 */
			status = "okay";                            /* in zephyr/boards/infineon/kit_psc3m5_evk/kit_psc3m5_evk.dts:52 */
			phandle = < 0x8 >;                          /* in zephyr/dts/arm/infineon/cat1b/psc3/system_clocks.dtsi:101 */
		};

		/* node '/clocks/path_mux2' defined in zephyr/dts/arm/infineon/cat1b/psc3/system_clocks.dtsi:75 */
		path_mux2: path_mux2 {
			#clock-cells = < 0x0 >;                     /* in zephyr/dts/arm/infineon/cat1b/psc3/system_clocks.dtsi:76 */
			compatible = "infineon,fixed-factor-clock"; /* in zephyr/dts/arm/infineon/cat1b/psc3/system_clocks.dtsi:77 */
			clocks = < &clk_iho >;                      /* in zephyr/dts/arm/infineon/cat1b/psc3/system_clocks.dtsi:78 */
			system-clock = < 0xb >;                     /* in zephyr/dts/arm/infineon/cat1b/psc3/system_clocks.dtsi:79 */
			instance = < 0x2 >;                         /* in zephyr/dts/arm/infineon/cat1b/psc3/system_clocks.dtsi:80 */
			source-path = < 0x6 >;                      /* in zephyr/dts/arm/infineon/cat1b/psc3/system_clocks.dtsi:81 */
			status = "okay";                            /* in zephyr/boards/infineon/kit_psc3m5_evk/kit_psc3m5_evk.dts:56 */
			phandle = < 0xa >;                          /* in zephyr/dts/arm/infineon/cat1b/psc3/system_clocks.dtsi:134 */
		};

		/* node '/clocks/path_mux3' defined in zephyr/dts/arm/infineon/cat1b/psc3/system_clocks.dtsi:86 */
		path_mux3: path_mux3 {
			#clock-cells = < 0x0 >;                     /* in zephyr/dts/arm/infineon/cat1b/psc3/system_clocks.dtsi:87 */
			compatible = "infineon,fixed-factor-clock"; /* in zephyr/dts/arm/infineon/cat1b/psc3/system_clocks.dtsi:88 */
			clocks = < &clk_iho >;                      /* in zephyr/dts/arm/infineon/cat1b/psc3/system_clocks.dtsi:89 */
			system-clock = < 0xb >;                     /* in zephyr/dts/arm/infineon/cat1b/psc3/system_clocks.dtsi:90 */
			instance = < 0x3 >;                         /* in zephyr/dts/arm/infineon/cat1b/psc3/system_clocks.dtsi:91 */
			source-path = < 0x6 >;                      /* in zephyr/dts/arm/infineon/cat1b/psc3/system_clocks.dtsi:92 */
			status = "okay";                            /* in zephyr/boards/infineon/kit_psc3m5_evk/kit_psc3m5_evk.dts:60 */
		};

		/* node '/clocks/clk_hf0' defined in zephyr/dts/arm/infineon/cat1b/psc3/system_clocks.dtsi:97 */
		clk_hf0: clk_hf0 {
			#clock-cells = < 0x0 >;                     /* in zephyr/dts/arm/infineon/cat1b/psc3/system_clocks.dtsi:98 */
			compatible = "infineon,fixed-factor-clock"; /* in zephyr/dts/arm/infineon/cat1b/psc3/system_clocks.dtsi:99 */
			clock-div = < 0x0 >;                        /* in zephyr/dts/arm/infineon/cat1b/psc3/system_clocks.dtsi:100 */
			clocks = < &path_mux1 >;                    /* in zephyr/dts/arm/infineon/cat1b/psc3/system_clocks.dtsi:101 */
			system-clock = < 0x12 >;                    /* in zephyr/dts/arm/infineon/cat1b/psc3/system_clocks.dtsi:102 */
			instance = < 0x0 >;                         /* in zephyr/dts/arm/infineon/cat1b/psc3/system_clocks.dtsi:103 */
			status = "okay";                            /* in zephyr/boards/infineon/kit_psc3m5_evk/kit_psc3m5_evk.dts:64 */
		};

		/* node '/clocks/clk_hf1' defined in zephyr/dts/arm/infineon/cat1b/psc3/system_clocks.dtsi:108 */
		clk_hf1: clk_hf1 {
			#clock-cells = < 0x0 >;                     /* in zephyr/dts/arm/infineon/cat1b/psc3/system_clocks.dtsi:109 */
			compatible = "infineon,fixed-factor-clock"; /* in zephyr/dts/arm/infineon/cat1b/psc3/system_clocks.dtsi:110 */
			clock-div = < 0x0 >;                        /* in zephyr/dts/arm/infineon/cat1b/psc3/system_clocks.dtsi:111 */
			clocks = < &path_mux1 >;                    /* in zephyr/dts/arm/infineon/cat1b/psc3/system_clocks.dtsi:112 */
			system-clock = < 0x12 >;                    /* in zephyr/dts/arm/infineon/cat1b/psc3/system_clocks.dtsi:113 */
			instance = < 0x1 >;                         /* in zephyr/dts/arm/infineon/cat1b/psc3/system_clocks.dtsi:114 */
			status = "okay";                            /* in zephyr/boards/infineon/kit_psc3m5_evk/kit_psc3m5_evk.dts:68 */
		};

		/* node '/clocks/clk_hf2' defined in zephyr/dts/arm/infineon/cat1b/psc3/system_clocks.dtsi:119 */
		clk_hf2: clk_hf2 {
			#clock-cells = < 0x0 >;                     /* in zephyr/dts/arm/infineon/cat1b/psc3/system_clocks.dtsi:120 */
			compatible = "infineon,fixed-factor-clock"; /* in zephyr/dts/arm/infineon/cat1b/psc3/system_clocks.dtsi:121 */
			clock-div = < 0x0 >;                        /* in zephyr/dts/arm/infineon/cat1b/psc3/system_clocks.dtsi:122 */
			clocks = < &path_mux0 >;                    /* in zephyr/dts/arm/infineon/cat1b/psc3/system_clocks.dtsi:123 */
			system-clock = < 0x12 >;                    /* in zephyr/dts/arm/infineon/cat1b/psc3/system_clocks.dtsi:124 */
			instance = < 0x2 >;                         /* in zephyr/dts/arm/infineon/cat1b/psc3/system_clocks.dtsi:125 */
			status = "okay";                            /* in zephyr/boards/infineon/kit_psc3m5_evk/kit_psc3m5_evk.dts:72 */
		};

		/* node '/clocks/clk_hf3' defined in zephyr/dts/arm/infineon/cat1b/psc3/system_clocks.dtsi:130 */
		clk_hf3: clk_hf3 {
			#clock-cells = < 0x0 >;                     /* in zephyr/dts/arm/infineon/cat1b/psc3/system_clocks.dtsi:131 */
			compatible = "infineon,fixed-factor-clock"; /* in zephyr/dts/arm/infineon/cat1b/psc3/system_clocks.dtsi:132 */
			clock-div = < 0x0 >;                        /* in zephyr/dts/arm/infineon/cat1b/psc3/system_clocks.dtsi:133 */
			clocks = < &path_mux2 >;                    /* in zephyr/dts/arm/infineon/cat1b/psc3/system_clocks.dtsi:134 */
			system-clock = < 0x12 >;                    /* in zephyr/dts/arm/infineon/cat1b/psc3/system_clocks.dtsi:135 */
			instance = < 0x3 >;                         /* in zephyr/dts/arm/infineon/cat1b/psc3/system_clocks.dtsi:136 */
			status = "okay";                            /* in zephyr/boards/infineon/kit_psc3m5_evk/kit_psc3m5_evk.dts:76 */
		};

		/* node '/clocks/clk_hf4' defined in zephyr/dts/arm/infineon/cat1b/psc3/system_clocks.dtsi:141 */
		clk_hf4: clk_hf4 {
			#clock-cells = < 0x0 >;                     /* in zephyr/dts/arm/infineon/cat1b/psc3/system_clocks.dtsi:142 */
			compatible = "infineon,fixed-factor-clock"; /* in zephyr/dts/arm/infineon/cat1b/psc3/system_clocks.dtsi:143 */
			clock-div = < 0x0 >;                        /* in zephyr/dts/arm/infineon/cat1b/psc3/system_clocks.dtsi:144 */
			clocks = < &path_mux0 >;                    /* in zephyr/dts/arm/infineon/cat1b/psc3/system_clocks.dtsi:145 */
			system-clock = < 0x12 >;                    /* in zephyr/dts/arm/infineon/cat1b/psc3/system_clocks.dtsi:146 */
			instance = < 0x4 >;                         /* in zephyr/dts/arm/infineon/cat1b/psc3/system_clocks.dtsi:147 */
			status = "disabled";                        /* in zephyr/dts/arm/infineon/cat1b/psc3/system_clocks.dtsi:148 */
		};
	};

	/* node '/peri0' defined in zephyr/dts/arm/infineon/cat1b/psc3/system_clocks.dtsi:152 */
	peri0: peri0 {

		/* node '/peri0/peri0_group0_24_5bit_0' defined in zephyr/dts/arm/infineon/cat1b/psc3/system_clocks.dtsi:155 */
		peri0_group0_24_5bit_0: peri0_group0_24_5bit_0 {
			#clock-cells = < 0x0 >;           /* in zephyr/dts/arm/infineon/cat1b/psc3/system_clocks.dtsi:156 */
			compatible = "infineon,peri-div"; /* in zephyr/dts/arm/infineon/cat1b/psc3/system_clocks.dtsi:157 */
			peri-group = [ 00 00 ];           /* in zephyr/dts/arm/infineon/cat1b/psc3/system_clocks.dtsi:158 */
			div-type = < 0x3 >;               /* in zephyr/dts/arm/infineon/cat1b/psc3/system_clocks.dtsi:159 */
			channel = < 0x0 >;                /* in zephyr/dts/arm/infineon/cat1b/psc3/system_clocks.dtsi:160 */
			clock-div = < 0x1 >;              /* in zephyr/dts/arm/infineon/cat1b/psc3/system_clocks.dtsi:161 */
			status = "disabled";              /* in zephyr/dts/arm/infineon/cat1b/psc3/system_clocks.dtsi:162 */
		};

		/* node '/peri0/peri0_group1_8bit_0' defined in zephyr/dts/arm/infineon/cat1b/psc3/system_clocks.dtsi:167 */
		peri0_group1_8bit_0: peri0_group1_8bit_0 {
			#clock-cells = < 0x0 >;           /* in zephyr/dts/arm/infineon/cat1b/psc3/system_clocks.dtsi:168 */
			compatible = "infineon,peri-div"; /* in zephyr/dts/arm/infineon/cat1b/psc3/system_clocks.dtsi:169 */
			peri-group = [ 00 01 ];           /* in zephyr/dts/arm/infineon/cat1b/psc3/system_clocks.dtsi:170 */
			div-type = < 0x0 >;               /* in zephyr/dts/arm/infineon/cat1b/psc3/system_clocks.dtsi:171 */
			channel = < 0x0 >;                /* in zephyr/dts/arm/infineon/cat1b/psc3/system_clocks.dtsi:172 */
			clock-div = < 0x1 >;              /* in zephyr/dts/arm/infineon/cat1b/psc3/system_clocks.dtsi:173 */
			status = "disabled";              /* in zephyr/dts/arm/infineon/cat1b/psc3/system_clocks.dtsi:174 */
		};

		/* node '/peri0/peri0_group4_8bit_0' defined in zephyr/dts/arm/infineon/cat1b/psc3/system_clocks.dtsi:179 */
		peri0_group4_8bit_0: peri0_group4_8bit_0 {
			#clock-cells = < 0x0 >;           /* in zephyr/dts/arm/infineon/cat1b/psc3/system_clocks.dtsi:180 */
			compatible = "infineon,peri-div"; /* in zephyr/dts/arm/infineon/cat1b/psc3/system_clocks.dtsi:181 */
			peri-group = [ 00 04 ];           /* in zephyr/dts/arm/infineon/cat1b/psc3/system_clocks.dtsi:182 */
			div-type = < 0x0 >;               /* in zephyr/dts/arm/infineon/cat1b/psc3/system_clocks.dtsi:183 */
			channel = < 0x0 >;                /* in zephyr/dts/arm/infineon/cat1b/psc3/system_clocks.dtsi:184 */
			status = "okay";                  /* in zephyr/boards/infineon/kit_psc3m5_evk/kit_psc3m5_evk.dts:41 */
			resource-type = < 0x18 >;         /* in zephyr/boards/infineon/kit_psc3m5_evk/kit_psc3m5_evk.dts:42 */
			resource-instance = < 0x3 >;      /* in zephyr/boards/infineon/kit_psc3m5_evk/kit_psc3m5_evk.dts:43 */
			clock-div = < 0x6d >;             /* in zephyr/boards/infineon/kit_psc3m5_evk/kit_psc3m5_evk.dts:44 */
			phandle = < 0x2 >;                /* in zephyr/boards/infineon/kit_psc3m5_evk/kit_psc3m5_evk.dts:34 */
		};

		/* node '/peri0/peri0_group4_8bit_1' defined in zephyr/dts/arm/infineon/cat1b/psc3/system_clocks.dtsi:189 */
		peri0_group4_8bit_1: peri0_group4_8bit_1 {
			#clock-cells = < 0x0 >;           /* in zephyr/dts/arm/infineon/cat1b/psc3/system_clocks.dtsi:190 */
			compatible = "infineon,peri-div"; /* in zephyr/dts/arm/infineon/cat1b/psc3/system_clocks.dtsi:191 */
			peri-group = [ 00 04 ];           /* in zephyr/dts/arm/infineon/cat1b/psc3/system_clocks.dtsi:192 */
			div-type = < 0x0 >;               /* in zephyr/dts/arm/infineon/cat1b/psc3/system_clocks.dtsi:193 */
			channel = < 0x1 >;                /* in zephyr/dts/arm/infineon/cat1b/psc3/system_clocks.dtsi:194 */
			clock-div = < 0x1 >;              /* in zephyr/dts/arm/infineon/cat1b/psc3/system_clocks.dtsi:195 */
			status = "disabled";              /* in zephyr/dts/arm/infineon/cat1b/psc3/system_clocks.dtsi:196 */
		};

		/* node '/peri0/peri0_group4_16bit_0' defined in zephyr/dts/arm/infineon/cat1b/psc3/system_clocks.dtsi:200 */
		peri0_group4_16bit_0: peri0_group4_16bit_0 {
			#clock-cells = < 0x0 >;           /* in zephyr/dts/arm/infineon/cat1b/psc3/system_clocks.dtsi:201 */
			compatible = "infineon,peri-div"; /* in zephyr/dts/arm/infineon/cat1b/psc3/system_clocks.dtsi:202 */
			peri-group = [ 00 04 ];           /* in zephyr/dts/arm/infineon/cat1b/psc3/system_clocks.dtsi:203 */
			div-type = < 0x1 >;               /* in zephyr/dts/arm/infineon/cat1b/psc3/system_clocks.dtsi:204 */
			channel = < 0x0 >;                /* in zephyr/dts/arm/infineon/cat1b/psc3/system_clocks.dtsi:205 */
			clock-div = < 0x1 >;              /* in zephyr/dts/arm/infineon/cat1b/psc3/system_clocks.dtsi:206 */
			status = "disabled";              /* in zephyr/dts/arm/infineon/cat1b/psc3/system_clocks.dtsi:207 */
		};

		/* node '/peri0/peri0_group4_16_5bit_0' defined in zephyr/dts/arm/infineon/cat1b/psc3/system_clocks.dtsi:211 */
		peri0_group4_16_5bit_0: peri0_group4_16_5bit_0 {
			#clock-cells = < 0x0 >;           /* in zephyr/dts/arm/infineon/cat1b/psc3/system_clocks.dtsi:212 */
			compatible = "infineon,peri-div"; /* in zephyr/dts/arm/infineon/cat1b/psc3/system_clocks.dtsi:213 */
			peri-group = [ 00 04 ];           /* in zephyr/dts/arm/infineon/cat1b/psc3/system_clocks.dtsi:214 */
			div-type = < 0x2 >;               /* in zephyr/dts/arm/infineon/cat1b/psc3/system_clocks.dtsi:215 */
			channel = < 0x0 >;                /* in zephyr/dts/arm/infineon/cat1b/psc3/system_clocks.dtsi:216 */
			clock-div = < 0x1 >;              /* in zephyr/dts/arm/infineon/cat1b/psc3/system_clocks.dtsi:217 */
			status = "disabled";              /* in zephyr/dts/arm/infineon/cat1b/psc3/system_clocks.dtsi:218 */
		};

		/* node '/peri0/peri0_group4_16_5bit_1' defined in zephyr/dts/arm/infineon/cat1b/psc3/system_clocks.dtsi:221 */
		peri0_group4_16_5bit_1: peri0_group4_16_5bit_1 {
			#clock-cells = < 0x0 >;           /* in zephyr/dts/arm/infineon/cat1b/psc3/system_clocks.dtsi:222 */
			compatible = "infineon,peri-div"; /* in zephyr/dts/arm/infineon/cat1b/psc3/system_clocks.dtsi:223 */
			peri-group = [ 00 04 ];           /* in zephyr/dts/arm/infineon/cat1b/psc3/system_clocks.dtsi:224 */
			div-type = < 0x2 >;               /* in zephyr/dts/arm/infineon/cat1b/psc3/system_clocks.dtsi:225 */
			channel = < 0x1 >;                /* in zephyr/dts/arm/infineon/cat1b/psc3/system_clocks.dtsi:226 */
			clock-div = < 0x1 >;              /* in zephyr/dts/arm/infineon/cat1b/psc3/system_clocks.dtsi:227 */
			status = "disabled";              /* in zephyr/dts/arm/infineon/cat1b/psc3/system_clocks.dtsi:228 */
		};

		/* node '/peri0/peri0_group4_16_5bit_2' defined in zephyr/dts/arm/infineon/cat1b/psc3/system_clocks.dtsi:231 */
		peri0_group4_16_5bit_2: peri0_group4_16_5bit_2 {
			#clock-cells = < 0x0 >;           /* in zephyr/dts/arm/infineon/cat1b/psc3/system_clocks.dtsi:232 */
			compatible = "infineon,peri-div"; /* in zephyr/dts/arm/infineon/cat1b/psc3/system_clocks.dtsi:233 */
			peri-group = [ 00 04 ];           /* in zephyr/dts/arm/infineon/cat1b/psc3/system_clocks.dtsi:234 */
			div-type = < 0x2 >;               /* in zephyr/dts/arm/infineon/cat1b/psc3/system_clocks.dtsi:235 */
			channel = < 0x2 >;                /* in zephyr/dts/arm/infineon/cat1b/psc3/system_clocks.dtsi:236 */
			clock-div = < 0x1 >;              /* in zephyr/dts/arm/infineon/cat1b/psc3/system_clocks.dtsi:237 */
			status = "disabled";              /* in zephyr/dts/arm/infineon/cat1b/psc3/system_clocks.dtsi:238 */
		};

		/* node '/peri0/peri0_group4_24_5bit_0' defined in zephyr/dts/arm/infineon/cat1b/psc3/system_clocks.dtsi:242 */
		peri0_group4_24_5bit_0: peri0_group4_24_5bit_0 {
			#clock-cells = < 0x0 >;           /* in zephyr/dts/arm/infineon/cat1b/psc3/system_clocks.dtsi:243 */
			compatible = "infineon,peri-div"; /* in zephyr/dts/arm/infineon/cat1b/psc3/system_clocks.dtsi:244 */
			peri-group = [ 00 04 ];           /* in zephyr/dts/arm/infineon/cat1b/psc3/system_clocks.dtsi:245 */
			div-type = < 0x3 >;               /* in zephyr/dts/arm/infineon/cat1b/psc3/system_clocks.dtsi:246 */
			channel = < 0x0 >;                /* in zephyr/dts/arm/infineon/cat1b/psc3/system_clocks.dtsi:247 */
			clock-div = < 0x1 >;              /* in zephyr/dts/arm/infineon/cat1b/psc3/system_clocks.dtsi:248 */
			status = "disabled";              /* in zephyr/dts/arm/infineon/cat1b/psc3/system_clocks.dtsi:249 */
		};

		/* node '/peri0/peri0_group5_8bit_0' defined in zephyr/dts/arm/infineon/cat1b/psc3/system_clocks.dtsi:254 */
		peri0_group5_8bit_0: peri0_group5_8bit_0 {
			#clock-cells = < 0x0 >;           /* in zephyr/dts/arm/infineon/cat1b/psc3/system_clocks.dtsi:255 */
			compatible = "infineon,peri-div"; /* in zephyr/dts/arm/infineon/cat1b/psc3/system_clocks.dtsi:256 */
			peri-group = [ 00 05 ];           /* in zephyr/dts/arm/infineon/cat1b/psc3/system_clocks.dtsi:257 */
			div-type = < 0x0 >;               /* in zephyr/dts/arm/infineon/cat1b/psc3/system_clocks.dtsi:258 */
			channel = < 0x0 >;                /* in zephyr/dts/arm/infineon/cat1b/psc3/system_clocks.dtsi:259 */
			clock-div = < 0x1 >;              /* in zephyr/dts/arm/infineon/cat1b/psc3/system_clocks.dtsi:260 */
			status = "disabled";              /* in zephyr/dts/arm/infineon/cat1b/psc3/system_clocks.dtsi:261 */
		};

		/* node '/peri0/peri0_group5_8bit_1' defined in zephyr/dts/arm/infineon/cat1b/psc3/system_clocks.dtsi:264 */
		peri0_group5_8bit_1: peri0_group5_8bit_1 {
			#clock-cells = < 0x0 >;           /* in zephyr/dts/arm/infineon/cat1b/psc3/system_clocks.dtsi:265 */
			compatible = "infineon,peri-div"; /* in zephyr/dts/arm/infineon/cat1b/psc3/system_clocks.dtsi:266 */
			peri-group = [ 00 05 ];           /* in zephyr/dts/arm/infineon/cat1b/psc3/system_clocks.dtsi:267 */
			div-type = < 0x0 >;               /* in zephyr/dts/arm/infineon/cat1b/psc3/system_clocks.dtsi:268 */
			channel = < 0x1 >;                /* in zephyr/dts/arm/infineon/cat1b/psc3/system_clocks.dtsi:269 */
			clock-div = < 0x1 >;              /* in zephyr/dts/arm/infineon/cat1b/psc3/system_clocks.dtsi:270 */
			status = "disabled";              /* in zephyr/dts/arm/infineon/cat1b/psc3/system_clocks.dtsi:271 */
		};

		/* node '/peri0/peri0_group5_8bit_2' defined in zephyr/dts/arm/infineon/cat1b/psc3/system_clocks.dtsi:274 */
		peri0_group5_8bit_2: peri0_group5_8bit_2 {
			#clock-cells = < 0x0 >;           /* in zephyr/dts/arm/infineon/cat1b/psc3/system_clocks.dtsi:275 */
			compatible = "infineon,peri-div"; /* in zephyr/dts/arm/infineon/cat1b/psc3/system_clocks.dtsi:276 */
			peri-group = [ 00 05 ];           /* in zephyr/dts/arm/infineon/cat1b/psc3/system_clocks.dtsi:277 */
			div-type = < 0x0 >;               /* in zephyr/dts/arm/infineon/cat1b/psc3/system_clocks.dtsi:278 */
			channel = < 0x2 >;                /* in zephyr/dts/arm/infineon/cat1b/psc3/system_clocks.dtsi:279 */
			clock-div = < 0x1 >;              /* in zephyr/dts/arm/infineon/cat1b/psc3/system_clocks.dtsi:280 */
			status = "disabled";              /* in zephyr/dts/arm/infineon/cat1b/psc3/system_clocks.dtsi:281 */
		};

		/* node '/peri0/peri0_group5_8bit_3' defined in zephyr/dts/arm/infineon/cat1b/psc3/system_clocks.dtsi:284 */
		peri0_group5_8bit_3: peri0_group5_8bit_3 {
			#clock-cells = < 0x0 >;           /* in zephyr/dts/arm/infineon/cat1b/psc3/system_clocks.dtsi:285 */
			compatible = "infineon,peri-div"; /* in zephyr/dts/arm/infineon/cat1b/psc3/system_clocks.dtsi:286 */
			peri-group = [ 00 05 ];           /* in zephyr/dts/arm/infineon/cat1b/psc3/system_clocks.dtsi:287 */
			div-type = < 0x0 >;               /* in zephyr/dts/arm/infineon/cat1b/psc3/system_clocks.dtsi:288 */
			channel = < 0x3 >;                /* in zephyr/dts/arm/infineon/cat1b/psc3/system_clocks.dtsi:289 */
			clock-div = < 0x1 >;              /* in zephyr/dts/arm/infineon/cat1b/psc3/system_clocks.dtsi:290 */
			status = "disabled";              /* in zephyr/dts/arm/infineon/cat1b/psc3/system_clocks.dtsi:291 */
		};

		/* node '/peri0/peri0_group5_8bit_4' defined in zephyr/dts/arm/infineon/cat1b/psc3/system_clocks.dtsi:294 */
		peri0_group5_8bit_4: peri0_group5_8bit_4 {
			#clock-cells = < 0x0 >;           /* in zephyr/dts/arm/infineon/cat1b/psc3/system_clocks.dtsi:295 */
			compatible = "infineon,peri-div"; /* in zephyr/dts/arm/infineon/cat1b/psc3/system_clocks.dtsi:296 */
			peri-group = [ 00 05 ];           /* in zephyr/dts/arm/infineon/cat1b/psc3/system_clocks.dtsi:297 */
			div-type = < 0x0 >;               /* in zephyr/dts/arm/infineon/cat1b/psc3/system_clocks.dtsi:298 */
			channel = < 0x4 >;                /* in zephyr/dts/arm/infineon/cat1b/psc3/system_clocks.dtsi:299 */
			clock-div = < 0x1 >;              /* in zephyr/dts/arm/infineon/cat1b/psc3/system_clocks.dtsi:300 */
			status = "disabled";              /* in zephyr/dts/arm/infineon/cat1b/psc3/system_clocks.dtsi:301 */
		};

		/* node '/peri0/peri0_group5_8bit_5' defined in zephyr/dts/arm/infineon/cat1b/psc3/system_clocks.dtsi:304 */
		peri0_group5_8bit_5: peri0_group5_8bit_5 {
			#clock-cells = < 0x0 >;           /* in zephyr/dts/arm/infineon/cat1b/psc3/system_clocks.dtsi:305 */
			compatible = "infineon,peri-div"; /* in zephyr/dts/arm/infineon/cat1b/psc3/system_clocks.dtsi:306 */
			peri-group = [ 00 05 ];           /* in zephyr/dts/arm/infineon/cat1b/psc3/system_clocks.dtsi:307 */
			div-type = < 0x0 >;               /* in zephyr/dts/arm/infineon/cat1b/psc3/system_clocks.dtsi:308 */
			channel = < 0x5 >;                /* in zephyr/dts/arm/infineon/cat1b/psc3/system_clocks.dtsi:309 */
			clock-div = < 0x1 >;              /* in zephyr/dts/arm/infineon/cat1b/psc3/system_clocks.dtsi:310 */
			status = "disabled";              /* in zephyr/dts/arm/infineon/cat1b/psc3/system_clocks.dtsi:311 */
		};

		/* node '/peri0/peri0_group5_8bit_6' defined in zephyr/dts/arm/infineon/cat1b/psc3/system_clocks.dtsi:314 */
		peri0_group5_8bit_6: peri0_group5_8bit_6 {
			#clock-cells = < 0x0 >;           /* in zephyr/dts/arm/infineon/cat1b/psc3/system_clocks.dtsi:315 */
			compatible = "infineon,peri-div"; /* in zephyr/dts/arm/infineon/cat1b/psc3/system_clocks.dtsi:316 */
			peri-group = [ 00 05 ];           /* in zephyr/dts/arm/infineon/cat1b/psc3/system_clocks.dtsi:317 */
			div-type = < 0x0 >;               /* in zephyr/dts/arm/infineon/cat1b/psc3/system_clocks.dtsi:318 */
			channel = < 0x6 >;                /* in zephyr/dts/arm/infineon/cat1b/psc3/system_clocks.dtsi:319 */
			clock-div = < 0x1 >;              /* in zephyr/dts/arm/infineon/cat1b/psc3/system_clocks.dtsi:320 */
			status = "disabled";              /* in zephyr/dts/arm/infineon/cat1b/psc3/system_clocks.dtsi:321 */
		};

		/* node '/peri0/peri0_group5_8bit_7' defined in zephyr/dts/arm/infineon/cat1b/psc3/system_clocks.dtsi:324 */
		peri0_group5_8bit_7: peri0_group5_8bit_7 {
			#clock-cells = < 0x0 >;           /* in zephyr/dts/arm/infineon/cat1b/psc3/system_clocks.dtsi:325 */
			compatible = "infineon,peri-div"; /* in zephyr/dts/arm/infineon/cat1b/psc3/system_clocks.dtsi:326 */
			peri-group = [ 00 05 ];           /* in zephyr/dts/arm/infineon/cat1b/psc3/system_clocks.dtsi:327 */
			div-type = < 0x0 >;               /* in zephyr/dts/arm/infineon/cat1b/psc3/system_clocks.dtsi:328 */
			channel = < 0x7 >;                /* in zephyr/dts/arm/infineon/cat1b/psc3/system_clocks.dtsi:329 */
			clock-div = < 0x1 >;              /* in zephyr/dts/arm/infineon/cat1b/psc3/system_clocks.dtsi:330 */
			status = "disabled";              /* in zephyr/dts/arm/infineon/cat1b/psc3/system_clocks.dtsi:331 */
		};

		/* node '/peri0/peri0_group5_8bit_8' defined in zephyr/dts/arm/infineon/cat1b/psc3/system_clocks.dtsi:334 */
		peri0_group5_8bit_8: peri0_group5_8bit_8 {
			#clock-cells = < 0x0 >;           /* in zephyr/dts/arm/infineon/cat1b/psc3/system_clocks.dtsi:335 */
			compatible = "infineon,peri-div"; /* in zephyr/dts/arm/infineon/cat1b/psc3/system_clocks.dtsi:336 */
			peri-group = [ 00 05 ];           /* in zephyr/dts/arm/infineon/cat1b/psc3/system_clocks.dtsi:337 */
			div-type = < 0x0 >;               /* in zephyr/dts/arm/infineon/cat1b/psc3/system_clocks.dtsi:338 */
			channel = < 0x8 >;                /* in zephyr/dts/arm/infineon/cat1b/psc3/system_clocks.dtsi:339 */
			clock-div = < 0x1 >;              /* in zephyr/dts/arm/infineon/cat1b/psc3/system_clocks.dtsi:340 */
			status = "disabled";              /* in zephyr/dts/arm/infineon/cat1b/psc3/system_clocks.dtsi:341 */
		};

		/* node '/peri0/peri0_group5_8bit_9' defined in zephyr/dts/arm/infineon/cat1b/psc3/system_clocks.dtsi:344 */
		peri0_group5_8bit_9: peri0_group5_8bit_9 {
			#clock-cells = < 0x0 >;           /* in zephyr/dts/arm/infineon/cat1b/psc3/system_clocks.dtsi:345 */
			compatible = "infineon,peri-div"; /* in zephyr/dts/arm/infineon/cat1b/psc3/system_clocks.dtsi:346 */
			peri-group = [ 00 05 ];           /* in zephyr/dts/arm/infineon/cat1b/psc3/system_clocks.dtsi:347 */
			div-type = < 0x0 >;               /* in zephyr/dts/arm/infineon/cat1b/psc3/system_clocks.dtsi:348 */
			channel = < 0x9 >;                /* in zephyr/dts/arm/infineon/cat1b/psc3/system_clocks.dtsi:349 */
			clock-div = < 0x1 >;              /* in zephyr/dts/arm/infineon/cat1b/psc3/system_clocks.dtsi:350 */
			status = "disabled";              /* in zephyr/dts/arm/infineon/cat1b/psc3/system_clocks.dtsi:351 */
		};

		/* node '/peri0/peri0_group5_16bit_0' defined in zephyr/dts/arm/infineon/cat1b/psc3/system_clocks.dtsi:355 */
		peri0_group5_16bit_0: peri0_group5_16bit_0 {
			#clock-cells = < 0x0 >;           /* in zephyr/dts/arm/infineon/cat1b/psc3/system_clocks.dtsi:356 */
			compatible = "infineon,peri-div"; /* in zephyr/dts/arm/infineon/cat1b/psc3/system_clocks.dtsi:357 */
			peri-group = [ 00 05 ];           /* in zephyr/dts/arm/infineon/cat1b/psc3/system_clocks.dtsi:358 */
			div-type = < 0x1 >;               /* in zephyr/dts/arm/infineon/cat1b/psc3/system_clocks.dtsi:359 */
			channel = < 0x0 >;                /* in zephyr/dts/arm/infineon/cat1b/psc3/system_clocks.dtsi:360 */
			clock-div = < 0x1 >;              /* in zephyr/dts/arm/infineon/cat1b/psc3/system_clocks.dtsi:361 */
			status = "disabled";              /* in zephyr/dts/arm/infineon/cat1b/psc3/system_clocks.dtsi:362 */
		};

		/* node '/peri0/peri0_group5_16bit_1' defined in zephyr/dts/arm/infineon/cat1b/psc3/system_clocks.dtsi:365 */
		peri0_group5_16bit_1: peri0_group5_16bit_1 {
			#clock-cells = < 0x0 >;           /* in zephyr/dts/arm/infineon/cat1b/psc3/system_clocks.dtsi:366 */
			compatible = "infineon,peri-div"; /* in zephyr/dts/arm/infineon/cat1b/psc3/system_clocks.dtsi:367 */
			peri-group = [ 00 05 ];           /* in zephyr/dts/arm/infineon/cat1b/psc3/system_clocks.dtsi:368 */
			div-type = < 0x1 >;               /* in zephyr/dts/arm/infineon/cat1b/psc3/system_clocks.dtsi:369 */
			channel = < 0x1 >;                /* in zephyr/dts/arm/infineon/cat1b/psc3/system_clocks.dtsi:370 */
			clock-div = < 0x1 >;              /* in zephyr/dts/arm/infineon/cat1b/psc3/system_clocks.dtsi:371 */
			status = "disabled";              /* in zephyr/dts/arm/infineon/cat1b/psc3/system_clocks.dtsi:372 */
		};

		/* node '/peri0/peri0_group5_16bit_2' defined in zephyr/dts/arm/infineon/cat1b/psc3/system_clocks.dtsi:375 */
		peri0_group5_16bit_2: peri0_group5_16bit_2 {
			#clock-cells = < 0x0 >;           /* in zephyr/dts/arm/infineon/cat1b/psc3/system_clocks.dtsi:376 */
			compatible = "infineon,peri-div"; /* in zephyr/dts/arm/infineon/cat1b/psc3/system_clocks.dtsi:377 */
			peri-group = [ 00 05 ];           /* in zephyr/dts/arm/infineon/cat1b/psc3/system_clocks.dtsi:378 */
			div-type = < 0x1 >;               /* in zephyr/dts/arm/infineon/cat1b/psc3/system_clocks.dtsi:379 */
			channel = < 0x2 >;                /* in zephyr/dts/arm/infineon/cat1b/psc3/system_clocks.dtsi:380 */
			clock-div = < 0x1 >;              /* in zephyr/dts/arm/infineon/cat1b/psc3/system_clocks.dtsi:381 */
			status = "disabled";              /* in zephyr/dts/arm/infineon/cat1b/psc3/system_clocks.dtsi:382 */
		};

		/* node '/peri0/peri0_group5_16bit_3' defined in zephyr/dts/arm/infineon/cat1b/psc3/system_clocks.dtsi:385 */
		peri0_group5_16bit_3: peri0_group5_16bit_3 {
			#clock-cells = < 0x0 >;           /* in zephyr/dts/arm/infineon/cat1b/psc3/system_clocks.dtsi:386 */
			compatible = "infineon,peri-div"; /* in zephyr/dts/arm/infineon/cat1b/psc3/system_clocks.dtsi:387 */
			peri-group = [ 00 05 ];           /* in zephyr/dts/arm/infineon/cat1b/psc3/system_clocks.dtsi:388 */
			div-type = < 0x1 >;               /* in zephyr/dts/arm/infineon/cat1b/psc3/system_clocks.dtsi:389 */
			channel = < 0x3 >;                /* in zephyr/dts/arm/infineon/cat1b/psc3/system_clocks.dtsi:390 */
			clock-div = < 0x1 >;              /* in zephyr/dts/arm/infineon/cat1b/psc3/system_clocks.dtsi:391 */
			status = "disabled";              /* in zephyr/dts/arm/infineon/cat1b/psc3/system_clocks.dtsi:392 */
		};

		/* node '/peri0/peri0_group6_16_5bit_0' defined in zephyr/dts/arm/infineon/cat1b/psc3/system_clocks.dtsi:397 */
		peri0_group6_16_5bit_0: peri0_group6_16_5bit_0 {
			#clock-cells = < 0x0 >;           /* in zephyr/dts/arm/infineon/cat1b/psc3/system_clocks.dtsi:398 */
			compatible = "infineon,peri-div"; /* in zephyr/dts/arm/infineon/cat1b/psc3/system_clocks.dtsi:399 */
			peri-group = [ 00 06 ];           /* in zephyr/dts/arm/infineon/cat1b/psc3/system_clocks.dtsi:400 */
			div-type = < 0x2 >;               /* in zephyr/dts/arm/infineon/cat1b/psc3/system_clocks.dtsi:401 */
			channel = < 0x0 >;                /* in zephyr/dts/arm/infineon/cat1b/psc3/system_clocks.dtsi:402 */
			clock-div = < 0x1 >;              /* in zephyr/dts/arm/infineon/cat1b/psc3/system_clocks.dtsi:403 */
			status = "disabled";              /* in zephyr/dts/arm/infineon/cat1b/psc3/system_clocks.dtsi:404 */
		};
	};

	/* node '/reserved-memory' defined in zephyr/dts/arm/infineon/cat1b/psc3/psc3_partition.dtsi:10 */
	reserved-memory {
		#address-cells = < 0x1 >; /* in zephyr/dts/arm/infineon/cat1b/psc3/psc3_partition.dtsi:11 */
		#size-cells = < 0x1 >;    /* in zephyr/dts/arm/infineon/cat1b/psc3/psc3_partition.dtsi:12 */
		ranges;                   /* in zephyr/dts/arm/infineon/cat1b/psc3/psc3_partition.dtsi:13 */

		/* node '/reserved-memory/sram0_s@34000000' defined in zephyr/dts/arm/infineon/cat1b/psc3/psc3_partition.dtsi:15 */
		sram0_s: sram0_s@34000000 {
			reg = < 0x34000000 0x4000 >; /* in zephyr/dts/arm/infineon/cat1b/psc3/psc3_partition.dtsi:17 */
		};

		/* node '/reserved-memory/sram0_ns@24004000' defined in zephyr/dts/arm/infineon/cat1b/psc3/psc3_partition.dtsi:20 */
		sram0_ns: sram0_ns@24004000 {
			reg = < 0x24004000 0xb000 >; /* in zephyr/dts/arm/infineon/cat1b/psc3/psc3_partition.dtsi:22 */
		};
	};

	/* node '/leds' defined in zephyr/boards/infineon/kit_psc3m5_evk/kit_psc3m5_evk-common.dtsi:16 */
	leds {
		compatible = "gpio-leds"; /* in zephyr/boards/infineon/kit_psc3m5_evk/kit_psc3m5_evk-common.dtsi:17 */

		/* node '/leds/led_0' defined in zephyr/boards/infineon/kit_psc3m5_evk/kit_psc3m5_evk-common.dtsi:19 */
		user_led0: led_0 {
			label = "LED_0";                /* in zephyr/boards/infineon/kit_psc3m5_evk/kit_psc3m5_evk-common.dtsi:20 */
			gpios = < &gpio_prt8 0x5 0x1 >; /* in zephyr/boards/infineon/kit_psc3m5_evk/kit_psc3m5_evk-common.dtsi:21 */
		};

		/* node '/leds/led_1' defined in zephyr/boards/infineon/kit_psc3m5_evk/kit_psc3m5_evk-common.dtsi:24 */
		user_led1: led_1 {
			label = "LED_1";                /* in zephyr/boards/infineon/kit_psc3m5_evk/kit_psc3m5_evk-common.dtsi:25 */
			gpios = < &gpio_prt8 0x4 0x1 >; /* in zephyr/boards/infineon/kit_psc3m5_evk/kit_psc3m5_evk-common.dtsi:26 */
		};
	};

	/* node '/gpio_keys' defined in zephyr/boards/infineon/kit_psc3m5_evk/kit_psc3m5_evk-common.dtsi:30 */
	gpio_keys {
		compatible = "gpio-keys"; /* in zephyr/boards/infineon/kit_psc3m5_evk/kit_psc3m5_evk-common.dtsi:31 */

		/* node '/gpio_keys/user_btn0' defined in zephyr/boards/infineon/kit_psc3m5_evk/kit_psc3m5_evk-common.dtsi:33 */
		user_bt0: user_btn0 {
			label = "SW_1";                  /* in zephyr/boards/infineon/kit_psc3m5_evk/kit_psc3m5_evk-common.dtsi:34 */
			gpios = < &gpio_prt5 0x0 0x11 >; /* in zephyr/boards/infineon/kit_psc3m5_evk/kit_psc3m5_evk-common.dtsi:35 */
			zephyr,code = < 0xb >;           /* in zephyr/boards/infineon/kit_psc3m5_evk/kit_psc3m5_evk-common.dtsi:36 */
		};

		/* node '/gpio_keys/user_btn1' defined in zephyr/boards/infineon/kit_psc3m5_evk/kit_psc3m5_evk-common.dtsi:39 */
		user_bt1: user_btn1 {
			label = "SW_2";                  /* in zephyr/boards/infineon/kit_psc3m5_evk/kit_psc3m5_evk-common.dtsi:40 */
			gpios = < &gpio_prt2 0x0 0x11 >; /* in zephyr/boards/infineon/kit_psc3m5_evk/kit_psc3m5_evk-common.dtsi:41 */
			zephyr,code = < 0x2 >;           /* in zephyr/boards/infineon/kit_psc3m5_evk/kit_psc3m5_evk-common.dtsi:42 */
		};
	};
};
